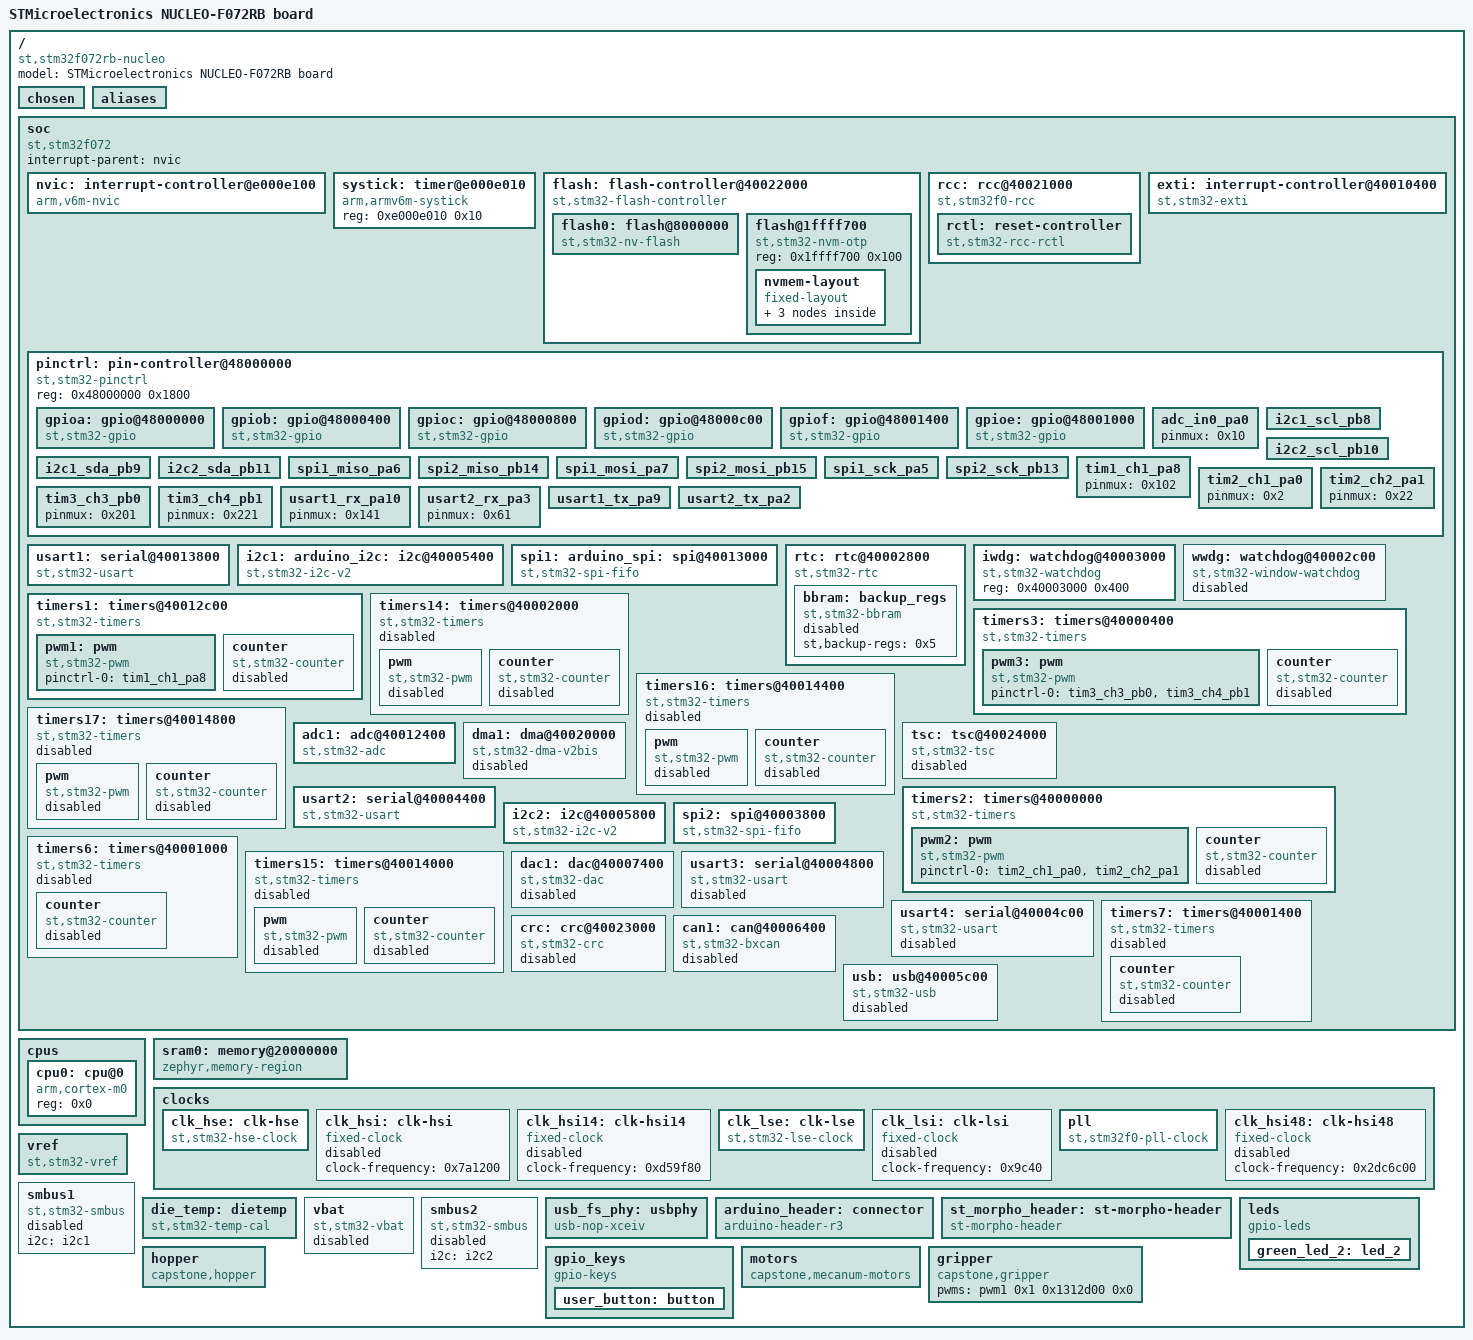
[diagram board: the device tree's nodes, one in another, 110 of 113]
/dts-v1/;

/* node '/' defined in zephyr\dts\common\skeleton.dtsi:9 */
/ {
	#address-cells = < 0x1 >;                         /* in zephyr\dts\common\skeleton.dtsi:10 */
	#size-cells = < 0x1 >;                            /* in zephyr\dts\common\skeleton.dtsi:11 */
	model = "STMicroelectronics NUCLEO-F072RB board"; /* in zephyr\boards\st\nucleo_f072rb\nucleo_f072rb.dts:15 */
	compatible = "st,stm32f072rb-nucleo";             /* in zephyr\boards\st\nucleo_f072rb\nucleo_f072rb.dts:16 */

	/* node '/chosen' defined in zephyr\dts\common\skeleton.dtsi:13 */
	chosen {
		zephyr,flash-controller = &flash; /* in zephyr\dts\arm\st\f0\stm32f0.dtsi:23 */
		zephyr,crc = &crc;                /* in zephyr\dts\arm\st\f0\stm32f071.dtsi:11 */
		zephyr,console = &usart2;         /* in zephyr\boards\st\nucleo_f072rb\nucleo_f072rb.dts:19 */
		zephyr,shell-uart = &usart2;      /* in zephyr\boards\st\nucleo_f072rb\nucleo_f072rb.dts:20 */
		zephyr,sram = &sram0;             /* in zephyr\boards\st\nucleo_f072rb\nucleo_f072rb.dts:21 */
		zephyr,flash = &flash0;           /* in zephyr\boards\st\nucleo_f072rb\nucleo_f072rb.dts:22 */
	};

	/* node '/aliases' defined in zephyr\dts\common\skeleton.dtsi:15 */
	aliases {
		led0 = &green_led_2;   /* in zephyr\boards\st\nucleo_f072rb\nucleo_f072rb.dts:45 */
		sw0 = &user_button;    /* in zephyr\boards\st\nucleo_f072rb\nucleo_f072rb.dts:46 */
		watchdog0 = &iwdg;     /* in zephyr\boards\st\nucleo_f072rb\nucleo_f072rb.dts:47 */
		die-temp0 = &die_temp; /* in zephyr\boards\st\nucleo_f072rb\nucleo_f072rb.dts:48 */
		volt-sensor0 = &vref;  /* in zephyr\boards\st\nucleo_f072rb\nucleo_f072rb.dts:49 */
	};

	/* node '/soc' defined in zephyr\dts\arm\armv6-m.dtsi:6 */
	soc {
		#address-cells = < 0x1 >;     /* in zephyr\dts\arm\armv6-m.dtsi:7 */
		#size-cells = < 0x1 >;        /* in zephyr\dts\arm\armv6-m.dtsi:8 */
		interrupt-parent = < &nvic >; /* in zephyr\dts\arm\armv6-m.dtsi:10 */
		ranges;                       /* in zephyr\dts\arm\armv6-m.dtsi:11 */
		compatible = "st,stm32f072",
		             "st,stm32f0",
		             "simple-bus";    /* in zephyr\dts\arm\st\f0\stm32f072.dtsi:11 */

		/* node '/soc/interrupt-controller@e000e100' defined in zephyr\dts\arm\armv6-m.dtsi:13 */
		nvic: interrupt-controller@e000e100 {
			#address-cells = < 0x1 >;            /* in zephyr\dts\arm\armv6-m.dtsi:14 */
			compatible = "arm,v6m-nvic";         /* in zephyr\dts\arm\armv6-m.dtsi:15 */
			reg = < 0xe000e100 0xc00 >;          /* in zephyr\dts\arm\armv6-m.dtsi:16 */
			interrupt-controller;                /* in zephyr\dts\arm\armv6-m.dtsi:17 */
			#interrupt-cells = < 0x2 >;          /* in zephyr\dts\arm\armv6-m.dtsi:18 */
			arm,num-irq-priority-bits = < 0x2 >; /* in zephyr\dts\arm\st\f0\stm32f0.dtsi:432 */
			phandle = < 0x1 >;                   /* in zephyr\dts\arm\armv6-m.dtsi:10 */
		};

		/* node '/soc/timer@e000e010' defined in zephyr\dts\arm\armv6-m.dtsi:21 */
		systick: timer@e000e010 {
			compatible = "arm,armv6m-systick"; /* in zephyr\dts\arm\armv6-m.dtsi:22 */
			reg = < 0xe000e010 0x10 >;         /* in zephyr\dts\arm\armv6-m.dtsi:23 */
		};

		/* node '/soc/flash-controller@40022000' defined in zephyr\dts\arm\st\f0\stm32f0.dtsi:86 */
		flash: flash-controller@40022000 {
			compatible = "st,stm32-flash-controller",
			             "st,stm32f1-flash-controller"; /* in zephyr\dts\arm\st\f0\stm32f0.dtsi:87 */
			reg = < 0x40022000 0x400 >;                 /* in zephyr\dts\arm\st\f0\stm32f0.dtsi:88 */
			interrupts = < 0x3 0x0 >;                   /* in zephyr\dts\arm\st\f0\stm32f0.dtsi:89 */
			clocks = < &rcc 0x14 0x10 >;                /* in zephyr\dts\arm\st\f0\stm32f0.dtsi:90 */
			#address-cells = < 0x1 >;                   /* in zephyr\dts\arm\st\f0\stm32f0.dtsi:92 */
			#size-cells = < 0x1 >;                      /* in zephyr\dts\arm\st\f0\stm32f0.dtsi:93 */

			/* node '/soc/flash-controller@40022000/flash@8000000' defined in zephyr\dts\arm\st\f0\stm32f0.dtsi:95 */
			flash0: flash@8000000 {
				compatible = "st,stm32-nv-flash",
				             "soc-nv-flash";      /* in zephyr\dts\arm\st\f0\stm32f0.dtsi:96 */
				write-block-size = < 0x2 >;       /* in zephyr\dts\arm\st\f0\stm32f0.dtsi:98 */
				max-erase-time = < 0x28 >;        /* in zephyr\dts\arm\st\f0\stm32f0.dtsi:100 */
				erase-block-size = < 0x800 >;     /* in zephyr\dts\arm\st\f0\stm32f071.dtsi:28 */
				reg = < 0x8000000 0x20000 >;      /* in zephyr\dts\arm\st\f0\stm32f072Xb.dtsi:16 */
			};

			/* node '/soc/flash-controller@40022000/flash@1ffff700' defined in zephyr\dts\arm\st\f0\stm32f0.dtsi:107 */
			flash@1ffff700 {
				compatible = "st,stm32-nvm-otp"; /* in zephyr\dts\arm\st\f0\stm32f0.dtsi:108 */
				reg = < 0x1ffff700 0x100 >;      /* in zephyr\dts\arm\st\f0\stm32f0.dtsi:109 */

				/* node '/soc/flash-controller@40022000/flash@1ffff700/nvmem-layout' defined in zephyr\dts\arm\st\f0\stm32f0.dtsi:111 */
				nvmem-layout {
					compatible = "fixed-layout"; /* in zephyr\dts\arm\st\f0\stm32f0.dtsi:112 */
					#address-cells = < 0x1 >;    /* in zephyr\dts\arm\st\f0\stm32f0.dtsi:113 */
					#size-cells = < 0x1 >;       /* in zephyr\dts\arm\st\f0\stm32f0.dtsi:114 */

					/* node '/soc/flash-controller@40022000/flash@1ffff700/nvmem-layout/ts-cal1@b8' defined in zephyr\dts\arm\st\f0\stm32f0.dtsi:116 */
					ts_cal1_otp: ts-cal1@b8 {
						reg = < 0xb8 0x2 >;          /* in zephyr\dts\arm\st\f0\stm32f0.dtsi:117 */
						#nvmem-cell-cells = < 0x0 >; /* in zephyr\dts\arm\st\f0\stm32f0.dtsi:118 */
						read-only;                   /* in zephyr\dts\arm\st\f0\stm32f0.dtsi:119 */
						phandle = < 0x1f >;          /* in zephyr\dts\arm\st\f0\stm32f031.dtsi:59 */
					};

					/* node '/soc/flash-controller@40022000/flash@1ffff700/nvmem-layout/vrefint@ba' defined in zephyr\dts\arm\st\f0\stm32f0.dtsi:122 */
					vrefint_otp: vrefint@ba {
						reg = < 0xba 0x2 >;          /* in zephyr\dts\arm\st\f0\stm32f0.dtsi:123 */
						#nvmem-cell-cells = < 0x0 >; /* in zephyr\dts\arm\st\f0\stm32f0.dtsi:124 */
						read-only;                   /* in zephyr\dts\arm\st\f0\stm32f0.dtsi:125 */
						phandle = < 0x1c >;          /* in zephyr\dts\arm\st\f0\stm32f0.dtsi:416 */
					};

					/* node '/soc/flash-controller@40022000/flash@1ffff700/nvmem-layout/ts-cal2@c2' defined in zephyr\dts\arm\st\f0\stm32f031.dtsi:47 */
					ts_cal2_otp: ts-cal2@c2 {
						reg = < 0xc2 0x2 >;          /* in zephyr\dts\arm\st\f0\stm32f031.dtsi:48 */
						#nvmem-cell-cells = < 0x0 >; /* in zephyr\dts\arm\st\f0\stm32f031.dtsi:49 */
						read-only;                   /* in zephyr\dts\arm\st\f0\stm32f031.dtsi:50 */
						phandle = < 0x20 >;          /* in zephyr\dts\arm\st\f0\stm32f031.dtsi:59 */
					};
				};
			};
		};

		/* node '/soc/rcc@40021000' defined in zephyr\dts\arm\st\f0\stm32f0.dtsi:131 */
		rcc: rcc@40021000 {
			compatible = "st,stm32f0-rcc";   /* in zephyr\dts\arm\st\f0\stm32f0.dtsi:132 */
			#clock-cells = < 0x2 >;          /* in zephyr\dts\arm\st\f0\stm32f0.dtsi:133 */
			reg = < 0x40021000 0x400 >;      /* in zephyr\dts\arm\st\f0\stm32f0.dtsi:134 */
			clocks = < &pll >;               /* in zephyr\boards\st\nucleo_f072rb\nucleo_f072rb.dts:71 */
			clock-frequency = < 0x2dc6c00 >; /* in zephyr\boards\st\nucleo_f072rb\nucleo_f072rb.dts:72 */
			ahb-prescaler = < 0x1 >;         /* in zephyr\boards\st\nucleo_f072rb\nucleo_f072rb.dts:73 */
			apb1-prescaler = < 0x2 >;        /* in zephyr\boards\st\nucleo_f072rb\nucleo_f072rb.dts:74 */
			phandle = < 0x2 >;               /* in zephyr\dts\arm\st\f0\stm32f0.dtsi:90 */

			/* node '/soc/rcc@40021000/reset-controller' defined in zephyr\dts\arm\st\f0\stm32f0.dtsi:136 */
			rctl: reset-controller {
				compatible = "st,stm32-rcc-rctl"; /* in zephyr\dts\arm\st\f0\stm32f0.dtsi:137 */
				#reset-cells = < 0x1 >;           /* in zephyr\dts\arm\st\f0\stm32f0.dtsi:138 */
				phandle = < 0x4 >;                /* in zephyr\dts\arm\st\f0\stm32f0.dtsi:206 */
			};
		};

		/* node '/soc/interrupt-controller@40010400' defined in zephyr\dts\arm\st\f0\stm32f0.dtsi:142 */
		exti: interrupt-controller@40010400 {
			compatible = "st,stm32-exti"; /* in zephyr\dts\arm\st\f0\stm32f0.dtsi:143 */
			interrupt-controller;         /* in zephyr\dts\arm\st\f0\stm32f0.dtsi:144 */
			#interrupt-cells = < 0x1 >;   /* in zephyr\dts\arm\st\f0\stm32f0.dtsi:145 */
			#address-cells = < 0x0 >;     /* in zephyr\dts\arm\st\f0\stm32f0.dtsi:146 */
			reg = < 0x40010400 0x400 >;   /* in zephyr\dts\arm\st\f0\stm32f0.dtsi:147 */
			clocks = < &rcc 0x18 0x1 >;   /* in zephyr\dts\arm\st\f0\stm32f0.dtsi:148 */
			num-lines = < 0x20 >;         /* in zephyr\dts\arm\st\f0\stm32f0.dtsi:149 */
			interrupts = < 0x5 0x0 >,
			             < 0x6 0x0 >,
			             < 0x7 0x0 >;     /* in zephyr\dts\arm\st\f0\stm32f0.dtsi:150 */
			interrupt-names = "line0-1",
			                  "line2-3",
			                  "line4-15"; /* in zephyr\dts\arm\st\f0\stm32f0.dtsi:151 */
			line-ranges = < 0x0 0x2 >,
			              < 0x2 0x2 >,
			              < 0x4 0xc >;    /* in zephyr\dts\arm\st\f0\stm32f0.dtsi:152 */
		};

		/* node '/soc/pin-controller@48000000' defined in zephyr\dts\arm\st\f0\stm32f0.dtsi:155 */
		pinctrl: pin-controller@48000000 {
			compatible = "st,stm32-pinctrl"; /* in zephyr\dts\arm\st\f0\stm32f0.dtsi:156 */
			#address-cells = < 0x1 >;        /* in zephyr\dts\arm\st\f0\stm32f0.dtsi:157 */
			#size-cells = < 0x1 >;           /* in zephyr\dts\arm\st\f0\stm32f0.dtsi:158 */
			reg = < 0x48000000 0x1800 >;     /* in zephyr\dts\arm\st\f0\stm32f0.dtsi:159 */

			/* node '/soc/pin-controller@48000000/gpio@48000000' defined in zephyr\dts\arm\st\f0\stm32f0.dtsi:161 */
			gpioa: gpio@48000000 {
				compatible = "st,stm32-gpio";   /* in zephyr\dts\arm\st\f0\stm32f0.dtsi:162 */
				gpio-controller;                /* in zephyr\dts\arm\st\f0\stm32f0.dtsi:163 */
				#gpio-cells = < 0x2 >;          /* in zephyr\dts\arm\st\f0\stm32f0.dtsi:164 */
				reg = < 0x48000000 0x400 >;     /* in zephyr\dts\arm\st\f0\stm32f0.dtsi:165 */
				clocks = < &rcc 0x14 0x20000 >; /* in zephyr\dts\arm\st\f0\stm32f0.dtsi:166 */
				phandle = < 0x22 >;             /* in zephyr\boards\st\nucleo_f072rb\arduino_r3_connector.dtsi:15 */
			};

			/* node '/soc/pin-controller@48000000/gpio@48000400' defined in zephyr\dts\arm\st\f0\stm32f0.dtsi:169 */
			gpiob: gpio@48000400 {
				compatible = "st,stm32-gpio";   /* in zephyr\dts\arm\st\f0\stm32f0.dtsi:170 */
				gpio-controller;                /* in zephyr\dts\arm\st\f0\stm32f0.dtsi:171 */
				#gpio-cells = < 0x2 >;          /* in zephyr\dts\arm\st\f0\stm32f0.dtsi:172 */
				reg = < 0x48000400 0x400 >;     /* in zephyr\dts\arm\st\f0\stm32f0.dtsi:173 */
				clocks = < &rcc 0x14 0x40000 >; /* in zephyr\dts\arm\st\f0\stm32f0.dtsi:174 */
				phandle = < 0xc >;              /* in zephyr\boards\st\nucleo_f072rb\nucleo_f072rb.dts:108 */
			};

			/* node '/soc/pin-controller@48000000/gpio@48000800' defined in zephyr\dts\arm\st\f0\stm32f0.dtsi:177 */
			gpioc: gpio@48000800 {
				compatible = "st,stm32-gpio";   /* in zephyr\dts\arm\st\f0\stm32f0.dtsi:178 */
				gpio-controller;                /* in zephyr\dts\arm\st\f0\stm32f0.dtsi:179 */
				#gpio-cells = < 0x2 >;          /* in zephyr\dts\arm\st\f0\stm32f0.dtsi:180 */
				reg = < 0x48000800 0x400 >;     /* in zephyr\dts\arm\st\f0\stm32f0.dtsi:181 */
				clocks = < &rcc 0x14 0x80000 >; /* in zephyr\dts\arm\st\f0\stm32f0.dtsi:182 */
				phandle = < 0x23 >;             /* in zephyr\boards\st\nucleo_f072rb\arduino_r3_connector.dtsi:15 */
			};

			/* node '/soc/pin-controller@48000000/gpio@48000c00' defined in zephyr\dts\arm\st\f0\stm32f0.dtsi:185 */
			gpiod: gpio@48000c00 {
				compatible = "st,stm32-gpio";    /* in zephyr\dts\arm\st\f0\stm32f0.dtsi:186 */
				gpio-controller;                 /* in zephyr\dts\arm\st\f0\stm32f0.dtsi:187 */
				#gpio-cells = < 0x2 >;           /* in zephyr\dts\arm\st\f0\stm32f0.dtsi:188 */
				reg = < 0x48000c00 0x400 >;      /* in zephyr\dts\arm\st\f0\stm32f0.dtsi:189 */
				clocks = < &rcc 0x14 0x100000 >; /* in zephyr\dts\arm\st\f0\stm32f0.dtsi:190 */
				phandle = < 0x24 >;              /* in zephyr\boards\st\nucleo_f072rb\st_morpho_connector.dtsi:15 */
			};

			/* node '/soc/pin-controller@48000000/gpio@48001400' defined in zephyr\dts\arm\st\f0\stm32f0.dtsi:193 */
			gpiof: gpio@48001400 {
				compatible = "st,stm32-gpio";    /* in zephyr\dts\arm\st\f0\stm32f0.dtsi:194 */
				gpio-controller;                 /* in zephyr\dts\arm\st\f0\stm32f0.dtsi:195 */
				#gpio-cells = < 0x2 >;           /* in zephyr\dts\arm\st\f0\stm32f0.dtsi:196 */
				reg = < 0x48001400 0x400 >;      /* in zephyr\dts\arm\st\f0\stm32f0.dtsi:197 */
				clocks = < &rcc 0x14 0x400000 >; /* in zephyr\dts\arm\st\f0\stm32f0.dtsi:198 */
				phandle = < 0x25 >;              /* in zephyr\boards\st\nucleo_f072rb\st_morpho_connector.dtsi:15 */
			};

			/* node '/soc/pin-controller@48000000/gpio@48001000' defined in zephyr\dts\arm\st\f0\stm32f071.dtsi:33 */
			gpioe: gpio@48001000 {
				compatible = "st,stm32-gpio";    /* in zephyr\dts\arm\st\f0\stm32f071.dtsi:34 */
				gpio-controller;                 /* in zephyr\dts\arm\st\f0\stm32f071.dtsi:35 */
				#gpio-cells = < 0x2 >;           /* in zephyr\dts\arm\st\f0\stm32f071.dtsi:36 */
				reg = < 0x48001000 0x400 >;      /* in zephyr\dts\arm\st\f0\stm32f071.dtsi:37 */
				clocks = < &rcc 0x14 0x200000 >; /* in zephyr\dts\arm\st\f0\stm32f071.dtsi:38 */
			};

			/* node '/soc/pin-controller@48000000/adc_in0_pa0' defined in modules\hal\stm32\dts\st\f0\stm32f072r(8-b)tx-pinctrl.dtsi:13 */
			adc_in0_pa0: adc_in0_pa0 {
				pinmux = < 0x10 >;  /* in modules\hal\stm32\dts\st\f0\stm32f072r(8-b)tx-pinctrl.dtsi:14 */
				phandle = < 0x10 >; /* in zephyr\boards\st\nucleo_f072rb\nucleo_f072rb.dts:123 */
			};

			/* node '/soc/pin-controller@48000000/i2c1_scl_pb8' defined in modules\hal\stm32\dts\st\f0\stm32f072r(8-b)tx-pinctrl.dtsi:383 */
			i2c1_scl_pb8: i2c1_scl_pb8 {
				pinmux = < 0x301 >; /* in modules\hal\stm32\dts\st\f0\stm32f072r(8-b)tx-pinctrl.dtsi:384 */
				bias-pull-up;       /* in modules\hal\stm32\dts\st\f0\stm32f072r(8-b)tx-pinctrl.dtsi:385 */
				drive-open-drain;   /* in modules\hal\stm32\dts\st\f0\stm32f072r(8-b)tx-pinctrl.dtsi:386 */
				phandle = < 0x7 >;  /* in zephyr\boards\st\nucleo_f072rb\nucleo_f072rb.dts:92 */
			};

			/* node '/soc/pin-controller@48000000/i2c2_scl_pb10' defined in modules\hal\stm32\dts\st\f0\stm32f072r(8-b)tx-pinctrl.dtsi:389 */
			i2c2_scl_pb10: i2c2_scl_pb10 {
				pinmux = < 0x341 >; /* in modules\hal\stm32\dts\st\f0\stm32f072r(8-b)tx-pinctrl.dtsi:390 */
				bias-pull-up;       /* in modules\hal\stm32\dts\st\f0\stm32f072r(8-b)tx-pinctrl.dtsi:391 */
				drive-open-drain;   /* in modules\hal\stm32\dts\st\f0\stm32f072r(8-b)tx-pinctrl.dtsi:392 */
				phandle = < 0x15 >; /* in zephyr\boards\st\nucleo_f072rb\nucleo_f072rb.dts:99 */
			};

			/* node '/soc/pin-controller@48000000/i2c1_sda_pb9' defined in modules\hal\stm32\dts\st\f0\stm32f072r(8-b)tx-pinctrl.dtsi:409 */
			i2c1_sda_pb9: i2c1_sda_pb9 {
				pinmux = < 0x321 >; /* in modules\hal\stm32\dts\st\f0\stm32f072r(8-b)tx-pinctrl.dtsi:410 */
				bias-pull-up;       /* in modules\hal\stm32\dts\st\f0\stm32f072r(8-b)tx-pinctrl.dtsi:411 */
				drive-open-drain;   /* in modules\hal\stm32\dts\st\f0\stm32f072r(8-b)tx-pinctrl.dtsi:412 */
				phandle = < 0x8 >;  /* in zephyr\boards\st\nucleo_f072rb\nucleo_f072rb.dts:92 */
			};

			/* node '/soc/pin-controller@48000000/i2c2_sda_pb11' defined in modules\hal\stm32\dts\st\f0\stm32f072r(8-b)tx-pinctrl.dtsi:415 */
			i2c2_sda_pb11: i2c2_sda_pb11 {
				pinmux = < 0x361 >; /* in modules\hal\stm32\dts\st\f0\stm32f072r(8-b)tx-pinctrl.dtsi:416 */
				bias-pull-up;       /* in modules\hal\stm32\dts\st\f0\stm32f072r(8-b)tx-pinctrl.dtsi:417 */
				drive-open-drain;   /* in modules\hal\stm32\dts\st\f0\stm32f072r(8-b)tx-pinctrl.dtsi:418 */
				phandle = < 0x16 >; /* in zephyr\boards\st\nucleo_f072rb\nucleo_f072rb.dts:99 */
			};

			/* node '/soc/pin-controller@48000000/spi1_miso_pa6' defined in modules\hal\stm32\dts\st\f0\stm32f072r(8-b)tx-pinctrl.dtsi:533 */
			spi1_miso_pa6: spi1_miso_pa6 {
				pinmux = < 0xc0 >;             /* in modules\hal\stm32\dts\st\f0\stm32f072r(8-b)tx-pinctrl.dtsi:534 */
				bias-pull-down;                /* in modules\hal\stm32\dts\st\f0\stm32f072r(8-b)tx-pinctrl.dtsi:535 */
				slew-rate = "very-high-speed"; /* in modules\hal\stm32\dts\st\f0\stm32f072r(8-b)tx-pinctrl.dtsi:536 */
				phandle = < 0xa >;             /* in zephyr\boards\st\nucleo_f072rb\nucleo_f072rb.dts:106 */
			};

			/* node '/soc/pin-controller@48000000/spi2_miso_pb14' defined in modules\hal\stm32\dts\st\f0\stm32f072r(8-b)tx-pinctrl.dtsi:545 */
			spi2_miso_pb14: spi2_miso_pb14 {
				pinmux = < 0x3c0 >;            /* in modules\hal\stm32\dts\st\f0\stm32f072r(8-b)tx-pinctrl.dtsi:546 */
				bias-pull-down;                /* in modules\hal\stm32\dts\st\f0\stm32f072r(8-b)tx-pinctrl.dtsi:547 */
				slew-rate = "very-high-speed"; /* in modules\hal\stm32\dts\st\f0\stm32f072r(8-b)tx-pinctrl.dtsi:548 */
				phandle = < 0x18 >;            /* in zephyr\boards\st\nucleo_f072rb\nucleo_f072rb.dts:113 */
			};

			/* node '/soc/pin-controller@48000000/spi1_mosi_pa7' defined in modules\hal\stm32\dts\st\f0\stm32f072r(8-b)tx-pinctrl.dtsi:559 */
			spi1_mosi_pa7: spi1_mosi_pa7 {
				pinmux = < 0xe0 >;             /* in modules\hal\stm32\dts\st\f0\stm32f072r(8-b)tx-pinctrl.dtsi:560 */
				bias-pull-down;                /* in modules\hal\stm32\dts\st\f0\stm32f072r(8-b)tx-pinctrl.dtsi:561 */
				slew-rate = "very-high-speed"; /* in modules\hal\stm32\dts\st\f0\stm32f072r(8-b)tx-pinctrl.dtsi:562 */
				phandle = < 0xb >;             /* in zephyr\boards\st\nucleo_f072rb\nucleo_f072rb.dts:106 */
			};

			/* node '/soc/pin-controller@48000000/spi2_mosi_pb15' defined in modules\hal\stm32\dts\st\f0\stm32f072r(8-b)tx-pinctrl.dtsi:571 */
			spi2_mosi_pb15: spi2_mosi_pb15 {
				pinmux = < 0x3e0 >;            /* in modules\hal\stm32\dts\st\f0\stm32f072r(8-b)tx-pinctrl.dtsi:572 */
				bias-pull-down;                /* in modules\hal\stm32\dts\st\f0\stm32f072r(8-b)tx-pinctrl.dtsi:573 */
				slew-rate = "very-high-speed"; /* in modules\hal\stm32\dts\st\f0\stm32f072r(8-b)tx-pinctrl.dtsi:574 */
				phandle = < 0x19 >;            /* in zephyr\boards\st\nucleo_f072rb\nucleo_f072rb.dts:113 */
			};

			/* node '/soc/pin-controller@48000000/spi1_sck_pa5' defined in modules\hal\stm32\dts\st\f0\stm32f072r(8-b)tx-pinctrl.dtsi:611 */
			spi1_sck_pa5: spi1_sck_pa5 {
				pinmux = < 0xa0 >;             /* in modules\hal\stm32\dts\st\f0\stm32f072r(8-b)tx-pinctrl.dtsi:612 */
				bias-pull-down;                /* in modules\hal\stm32\dts\st\f0\stm32f072r(8-b)tx-pinctrl.dtsi:613 */
				slew-rate = "very-high-speed"; /* in modules\hal\stm32\dts\st\f0\stm32f072r(8-b)tx-pinctrl.dtsi:614 */
				phandle = < 0x9 >;             /* in zephyr\boards\st\nucleo_f072rb\nucleo_f072rb.dts:106 */
			};

			/* node '/soc/pin-controller@48000000/spi2_sck_pb13' defined in modules\hal\stm32\dts\st\f0\stm32f072r(8-b)tx-pinctrl.dtsi:629 */
			spi2_sck_pb13: spi2_sck_pb13 {
				pinmux = < 0x3a0 >;            /* in modules\hal\stm32\dts\st\f0\stm32f072r(8-b)tx-pinctrl.dtsi:630 */
				bias-pull-down;                /* in modules\hal\stm32\dts\st\f0\stm32f072r(8-b)tx-pinctrl.dtsi:631 */
				slew-rate = "very-high-speed"; /* in modules\hal\stm32\dts\st\f0\stm32f072r(8-b)tx-pinctrl.dtsi:632 */
				phandle = < 0x17 >;            /* in zephyr\boards\st\nucleo_f072rb\nucleo_f072rb.dts:113 */
			};

			/* node '/soc/pin-controller@48000000/tim1_ch1_pa8' defined in modules\hal\stm32\dts\st\f0\stm32f072r(8-b)tx-pinctrl.dtsi:671 */
			tim1_ch1_pa8: tim1_ch1_pa8 {
				pinmux = < 0x102 >; /* in modules\hal\stm32\dts\st\f0\stm32f072r(8-b)tx-pinctrl.dtsi:672 */
				phandle = < 0xd >;  /* in ..\Documents\capstone\zephyr\nucleo_f072rb.overlay:60 */
			};

			/* node '/soc/pin-controller@48000000/tim2_ch1_pa0' defined in modules\hal\stm32\dts\st\f0\stm32f072r(8-b)tx-pinctrl.dtsi:707 */
			tim2_ch1_pa0: tim2_ch1_pa0 {
				pinmux = < 0x2 >;   /* in modules\hal\stm32\dts\st\f0\stm32f072r(8-b)tx-pinctrl.dtsi:708 */
				phandle = < 0x11 >; /* in ..\Documents\capstone\zephyr\nucleo_f072rb.overlay:33 */
			};

			/* node '/soc/pin-controller@48000000/tim2_ch2_pa1' defined in modules\hal\stm32\dts\st\f0\stm32f072r(8-b)tx-pinctrl.dtsi:711 */
			tim2_ch2_pa1: tim2_ch2_pa1 {
				pinmux = < 0x22 >;  /* in modules\hal\stm32\dts\st\f0\stm32f072r(8-b)tx-pinctrl.dtsi:712 */
				phandle = < 0x12 >; /* in ..\Documents\capstone\zephyr\nucleo_f072rb.overlay:33 */
			};

			/* node '/soc/pin-controller@48000000/tim3_ch3_pb0' defined in modules\hal\stm32\dts\st\f0\stm32f072r(8-b)tx-pinctrl.dtsi:751 */
			tim3_ch3_pb0: tim3_ch3_pb0 {
				pinmux = < 0x201 >; /* in modules\hal\stm32\dts\st\f0\stm32f072r(8-b)tx-pinctrl.dtsi:752 */
				phandle = < 0xe >;  /* in ..\Documents\capstone\zephyr\nucleo_f072rb.overlay:45 */
			};

			/* node '/soc/pin-controller@48000000/tim3_ch4_pb1' defined in modules\hal\stm32\dts\st\f0\stm32f072r(8-b)tx-pinctrl.dtsi:755 */
			tim3_ch4_pb1: tim3_ch4_pb1 {
				pinmux = < 0x221 >; /* in modules\hal\stm32\dts\st\f0\stm32f072r(8-b)tx-pinctrl.dtsi:756 */
				phandle = < 0xf >;  /* in ..\Documents\capstone\zephyr\nucleo_f072rb.overlay:45 */
			};

			/* node '/soc/pin-controller@48000000/usart1_rx_pa10' defined in modules\hal\stm32\dts\st\f0\stm32f072r(8-b)tx-pinctrl.dtsi:1042 */
			usart1_rx_pa10: usart1_rx_pa10 {
				pinmux = < 0x141 >; /* in modules\hal\stm32\dts\st\f0\stm32f072r(8-b)tx-pinctrl.dtsi:1043 */
				phandle = < 0x6 >;  /* in zephyr\boards\st\nucleo_f072rb\nucleo_f072rb.dts:78 */
			};

			/* node '/soc/pin-controller@48000000/usart2_rx_pa3' defined in modules\hal\stm32\dts\st\f0\stm32f072r(8-b)tx-pinctrl.dtsi:1050 */
			usart2_rx_pa3: usart2_rx_pa3 {
				pinmux = < 0x61 >;  /* in modules\hal\stm32\dts\st\f0\stm32f072r(8-b)tx-pinctrl.dtsi:1051 */
				phandle = < 0x14 >; /* in zephyr\boards\st\nucleo_f072rb\nucleo_f072rb.dts:85 */
			};

			/* node '/soc/pin-controller@48000000/usart1_tx_pa9' defined in modules\hal\stm32\dts\st\f0\stm32f072r(8-b)tx-pinctrl.dtsi:1080 */
			usart1_tx_pa9: usart1_tx_pa9 {
				pinmux = < 0x121 >; /* in modules\hal\stm32\dts\st\f0\stm32f072r(8-b)tx-pinctrl.dtsi:1081 */
				bias-pull-up;       /* in modules\hal\stm32\dts\st\f0\stm32f072r(8-b)tx-pinctrl.dtsi:1082 */
				phandle = < 0x5 >;  /* in zephyr\boards\st\nucleo_f072rb\nucleo_f072rb.dts:78 */
			};

			/* node '/soc/pin-controller@48000000/usart2_tx_pa2' defined in modules\hal\stm32\dts\st\f0\stm32f072r(8-b)tx-pinctrl.dtsi:1090 */
			usart2_tx_pa2: usart2_tx_pa2 {
				pinmux = < 0x41 >;  /* in modules\hal\stm32\dts\st\f0\stm32f072r(8-b)tx-pinctrl.dtsi:1091 */
				bias-pull-up;       /* in modules\hal\stm32\dts\st\f0\stm32f072r(8-b)tx-pinctrl.dtsi:1092 */
				phandle = < 0x13 >; /* in zephyr\boards\st\nucleo_f072rb\nucleo_f072rb.dts:85 */
			};
		};

		/* node '/soc/serial@40013800' defined in zephyr\dts\arm\st\f0\stm32f0.dtsi:202 */
		usart1: serial@40013800 {
			compatible = "st,stm32-usart",
			             "st,stm32-uart";                   /* in zephyr\dts\arm\st\f0\stm32f0.dtsi:203 */
			reg = < 0x40013800 0x400 >;                     /* in zephyr\dts\arm\st\f0\stm32f0.dtsi:204 */
			clocks = < &rcc 0x18 0x4000 >;                  /* in zephyr\dts\arm\st\f0\stm32f0.dtsi:205 */
			resets = < &rctl 0x18e >;                       /* in zephyr\dts\arm\st\f0\stm32f0.dtsi:206 */
			interrupts = < 0x1b 0x0 >;                      /* in zephyr\dts\arm\st\f0\stm32f0.dtsi:207 */
			pinctrl-0 = < &usart1_tx_pa9 &usart1_rx_pa10 >; /* in zephyr\boards\st\nucleo_f072rb\nucleo_f072rb.dts:78 */
			pinctrl-names = "default";                      /* in zephyr\boards\st\nucleo_f072rb\nucleo_f072rb.dts:79 */
			current-speed = < 0x1c200 >;                    /* in zephyr\boards\st\nucleo_f072rb\nucleo_f072rb.dts:80 */
			status = "okay";                                /* in zephyr\boards\st\nucleo_f072rb\nucleo_f072rb.dts:81 */
		};

		/* node '/soc/i2c@40005400' defined in zephyr\dts\arm\st\f0\stm32f0.dtsi:211 */
		i2c1: arduino_i2c: i2c@40005400 {
			compatible = "st,stm32-i2c-v2";              /* in zephyr\dts\arm\st\f0\stm32f0.dtsi:212 */
			#address-cells = < 0x1 >;                    /* in zephyr\dts\arm\st\f0\stm32f0.dtsi:214 */
			#size-cells = < 0x0 >;                       /* in zephyr\dts\arm\st\f0\stm32f0.dtsi:215 */
			reg = < 0x40005400 0x400 >;                  /* in zephyr\dts\arm\st\f0\stm32f0.dtsi:216 */
			clocks = < &rcc 0x1c 0x200000 >,
			         < &rcc 0x1 0x1040030 >;             /* in zephyr\dts\arm\st\f0\stm32f0.dtsi:217 */
			interrupts = < 0x17 0x0 >;                   /* in zephyr\dts\arm\st\f0\stm32f0.dtsi:222 */
			interrupt-names = "combined";                /* in zephyr\dts\arm\st\f0\stm32f0.dtsi:223 */
			pinctrl-0 = < &i2c1_scl_pb8 &i2c1_sda_pb9 >; /* in zephyr\boards\st\nucleo_f072rb\nucleo_f072rb.dts:92 */
			pinctrl-names = "default";                   /* in zephyr\boards\st\nucleo_f072rb\nucleo_f072rb.dts:93 */
			status = "okay";                             /* in zephyr\boards\st\nucleo_f072rb\nucleo_f072rb.dts:94 */
			clock-frequency = < 0x61a80 >;               /* in zephyr\boards\st\nucleo_f072rb\nucleo_f072rb.dts:95 */
			phandle = < 0x1e >;                          /* in zephyr\dts\arm\st\f0\stm32f0.dtsi:426 */
		};

		/* node '/soc/spi@40013000' defined in zephyr\dts\arm\st\f0\stm32f0.dtsi:227 */
		spi1: arduino_spi: spi@40013000 {
			compatible = "st,stm32-spi-fifo",
			             "st,stm32-spi";                                 /* in zephyr\dts\arm\st\f0\stm32f0.dtsi:228 */
			#address-cells = < 0x1 >;                                    /* in zephyr\dts\arm\st\f0\stm32f0.dtsi:229 */
			#size-cells = < 0x0 >;                                       /* in zephyr\dts\arm\st\f0\stm32f0.dtsi:230 */
			reg = < 0x40013000 0x400 >;                                  /* in zephyr\dts\arm\st\f0\stm32f0.dtsi:231 */
			clocks = < &rcc 0x18 0x1000 >;                               /* in zephyr\dts\arm\st\f0\stm32f0.dtsi:232 */
			interrupts = < 0x19 0x3 >;                                   /* in zephyr\dts\arm\st\f0\stm32f0.dtsi:233 */
			st,spi-data-width = "full-4-to-16-bit";                      /* in zephyr\dts\arm\st\f0\stm32f0.dtsi:234 */
			pinctrl-0 = < &spi1_sck_pa5 &spi1_miso_pa6 &spi1_mosi_pa7 >; /* in zephyr\boards\st\nucleo_f072rb\nucleo_f072rb.dts:106 */
			pinctrl-names = "default";                                   /* in zephyr\boards\st\nucleo_f072rb\nucleo_f072rb.dts:107 */
			cs-gpios = < &gpiob 0x6 0x11 >;                              /* in zephyr\boards\st\nucleo_f072rb\nucleo_f072rb.dts:108 */
			status = "okay";                                             /* in zephyr\boards\st\nucleo_f072rb\nucleo_f072rb.dts:109 */
		};

		/* node '/soc/rtc@40002800' defined in zephyr\dts\arm\st\f0\stm32f0.dtsi:238 */
		rtc: rtc@40002800 {
			compatible = "st,stm32-rtc";       /* in zephyr\dts\arm\st\f0\stm32f0.dtsi:239 */
			reg = < 0x40002800 0x400 >;        /* in zephyr\dts\arm\st\f0\stm32f0.dtsi:240 */
			interrupts = < 0x2 0x0 >;          /* in zephyr\dts\arm\st\f0\stm32f0.dtsi:242 */
			prescaler = < 0x8000 >;            /* in zephyr\dts\arm\st\f0\stm32f0.dtsi:243 */
			alarms-count = < 0x1 >;            /* in zephyr\dts\arm\st\f0\stm32f0.dtsi:244 */
			alrm-exti-line = < 0x11 >;         /* in zephyr\dts\arm\st\f0\stm32f0.dtsi:245 */
			clocks = < &rcc 0x1c 0x10000000 >,
			         < &rcc 0x2 0x1280020 >;   /* in zephyr\boards\st\nucleo_f072rb\nucleo_f072rb.dts:131 */
			status = "okay";                   /* in zephyr\boards\st\nucleo_f072rb\nucleo_f072rb.dts:133 */

			/* node '/soc/rtc@40002800/backup_regs' defined in zephyr\dts\arm\st\f0\stm32f031.dtsi:37 */
			bbram: backup_regs {
				compatible = "st,stm32-bbram"; /* in zephyr\dts\arm\st\f0\stm32f031.dtsi:38 */
				st,backup-regs = < 0x5 >;      /* in zephyr\dts\arm\st\f0\stm32f031.dtsi:39 */
				status = "disabled";           /* in zephyr\dts\arm\st\f0\stm32f031.dtsi:40 */
			};
		};

		/* node '/soc/watchdog@40003000' defined in zephyr\dts\arm\st\f0\stm32f0.dtsi:249 */
		iwdg: watchdog@40003000 {
			compatible = "st,stm32-watchdog"; /* in zephyr\dts\arm\st\f0\stm32f0.dtsi:250 */
			reg = < 0x40003000 0x400 >;       /* in zephyr\dts\arm\st\f0\stm32f0.dtsi:251 */
			status = "okay";                  /* in zephyr\boards\st\nucleo_f072rb\nucleo_f072rb.dts:119 */
		};

		/* node '/soc/watchdog@40002c00' defined in zephyr\dts\arm\st\f0\stm32f0.dtsi:255 */
		wwdg: watchdog@40002c00 {
			compatible = "st,stm32-window-watchdog"; /* in zephyr\dts\arm\st\f0\stm32f0.dtsi:256 */
			reg = < 0x40002c00 0x400 >;              /* in zephyr\dts\arm\st\f0\stm32f0.dtsi:257 */
			clocks = < &rcc 0x1c 0x800 >;            /* in zephyr\dts\arm\st\f0\stm32f0.dtsi:258 */
			interrupts = < 0x0 0x2 >;                /* in zephyr\dts\arm\st\f0\stm32f0.dtsi:259 */
			status = "disabled";                     /* in zephyr\dts\arm\st\f0\stm32f0.dtsi:260 */
		};

		/* node '/soc/timers@40012c00' defined in zephyr\dts\arm\st\f0\stm32f0.dtsi:263 */
		timers1: timers@40012c00 {
			compatible = "st,stm32-timers";     /* in zephyr\dts\arm\st\f0\stm32f0.dtsi:264 */
			reg = < 0x40012c00 0x400 >;         /* in zephyr\dts\arm\st\f0\stm32f0.dtsi:265 */
			clocks = < &rcc 0x18 0x800 >,
			         < &rcc 0x8 0xff >;         /* in zephyr\dts\arm\st\f0\stm32f0.dtsi:266 */
			resets = < &rctl 0x18b >;           /* in zephyr\dts\arm\st\f0\stm32f0.dtsi:268 */
			interrupts = < 0xd 0x0 >,
			             < 0xe 0x0 >;           /* in zephyr\dts\arm\st\f0\stm32f0.dtsi:269 */
			interrupt-names = "brk_up_trg_com",
			                  "cc";             /* in zephyr\dts\arm\st\f0\stm32f0.dtsi:270 */
			st,prescaler = < 0x2f >;            /* in ..\Documents\capstone\zephyr\nucleo_f072rb.overlay:54 */
			status = "okay";                    /* in ..\Documents\capstone\zephyr\nucleo_f072rb.overlay:55 */

			/* node '/soc/timers@40012c00/pwm' defined in zephyr\dts\arm\st\f0\stm32f0.dtsi:274 */
			pwm1: pwm {
				compatible = "st,stm32-pwm";   /* in zephyr\dts\arm\st\f0\stm32f0.dtsi:275 */
				#pwm-cells = < 0x3 >;          /* in zephyr\dts\arm\st\f0\stm32f0.dtsi:277 */
				status = "okay";               /* in ..\Documents\capstone\zephyr\nucleo_f072rb.overlay:58 */
				pinctrl-0 = < &tim1_ch1_pa8 >; /* in ..\Documents\capstone\zephyr\nucleo_f072rb.overlay:60 */
				pinctrl-names = "default";     /* in ..\Documents\capstone\zephyr\nucleo_f072rb.overlay:61 */
				phandle = < 0x28 >;            /* in ..\Documents\capstone\zephyr\nucleo_f072rb.overlay:83 */
			};

			/* node '/soc/timers@40012c00/counter' defined in zephyr\dts\arm\st\f0\stm32f0.dtsi:280 */
			counter {
				compatible = "st,stm32-counter"; /* in zephyr\dts\arm\st\f0\stm32f0.dtsi:281 */
				status = "disabled";             /* in zephyr\dts\arm\st\f0\stm32f0.dtsi:282 */
			};
		};

		/* node '/soc/timers@40000400' defined in zephyr\dts\arm\st\f0\stm32f0.dtsi:286 */
		timers3: timers@40000400 {
			compatible = "st,stm32-timers"; /* in zephyr\dts\arm\st\f0\stm32f0.dtsi:287 */
			reg = < 0x40000400 0x400 >;     /* in zephyr\dts\arm\st\f0\stm32f0.dtsi:288 */
			clocks = < &rcc 0x1c 0x2 >,
			         < &rcc 0x8 0xff >;     /* in zephyr\dts\arm\st\f0\stm32f0.dtsi:289 */
			resets = < &rctl 0x201 >;       /* in zephyr\dts\arm\st\f0\stm32f0.dtsi:291 */
			interrupts = < 0x10 0x0 >;      /* in zephyr\dts\arm\st\f0\stm32f0.dtsi:292 */
			interrupt-names = "global";     /* in zephyr\dts\arm\st\f0\stm32f0.dtsi:293 */
			st,prescaler = < 0x0 >;         /* in ..\Documents\capstone\zephyr\nucleo_f072rb.overlay:39 */
			status = "okay";                /* in ..\Documents\capstone\zephyr\nucleo_f072rb.overlay:40 */

			/* node '/soc/timers@40000400/pwm' defined in zephyr\dts\arm\st\f0\stm32f0.dtsi:297 */
			pwm3: pwm {
				compatible = "st,stm32-pwm";                 /* in zephyr\dts\arm\st\f0\stm32f0.dtsi:298 */
				#pwm-cells = < 0x3 >;                        /* in zephyr\dts\arm\st\f0\stm32f0.dtsi:300 */
				status = "okay";                             /* in ..\Documents\capstone\zephyr\nucleo_f072rb.overlay:43 */
				pinctrl-0 = < &tim3_ch3_pb0 &tim3_ch4_pb1 >; /* in ..\Documents\capstone\zephyr\nucleo_f072rb.overlay:45 */
				pinctrl-names = "default";                   /* in ..\Documents\capstone\zephyr\nucleo_f072rb.overlay:46 */
				phandle = < 0x27 >;                          /* in ..\Documents\capstone\zephyr\nucleo_f072rb.overlay:69 */
			};

			/* node '/soc/timers@40000400/counter' defined in zephyr\dts\arm\st\f0\stm32f0.dtsi:303 */
			counter {
				compatible = "st,stm32-counter"; /* in zephyr\dts\arm\st\f0\stm32f0.dtsi:304 */
				status = "disabled";             /* in zephyr\dts\arm\st\f0\stm32f0.dtsi:305 */
			};
		};

		/* node '/soc/timers@40002000' defined in zephyr\dts\arm\st\f0\stm32f0.dtsi:309 */
		timers14: timers@40002000 {
			compatible = "st,stm32-timers"; /* in zephyr\dts\arm\st\f0\stm32f0.dtsi:310 */
			reg = < 0x40002000 0x400 >;     /* in zephyr\dts\arm\st\f0\stm32f0.dtsi:311 */
			clocks = < &rcc 0x1c 0x100 >,
			         < &rcc 0x8 0xff >;     /* in zephyr\dts\arm\st\f0\stm32f0.dtsi:312 */
			resets = < &rctl 0x208 >;       /* in zephyr\dts\arm\st\f0\stm32f0.dtsi:314 */
			interrupts = < 0x13 0x0 >;      /* in zephyr\dts\arm\st\f0\stm32f0.dtsi:315 */
			interrupt-names = "global";     /* in zephyr\dts\arm\st\f0\stm32f0.dtsi:316 */
			st,prescaler = < 0x0 >;         /* in zephyr\dts\arm\st\f0\stm32f0.dtsi:317 */
			status = "disabled";            /* in zephyr\dts\arm\st\f0\stm32f0.dtsi:318 */

			/* node '/soc/timers@40002000/pwm' defined in zephyr\dts\arm\st\f0\stm32f0.dtsi:320 */
			pwm {
				compatible = "st,stm32-pwm"; /* in zephyr\dts\arm\st\f0\stm32f0.dtsi:321 */
				status = "disabled";         /* in zephyr\dts\arm\st\f0\stm32f0.dtsi:322 */
				#pwm-cells = < 0x3 >;        /* in zephyr\dts\arm\st\f0\stm32f0.dtsi:323 */
			};

			/* node '/soc/timers@40002000/counter' defined in zephyr\dts\arm\st\f0\stm32f0.dtsi:326 */
			counter {
				compatible = "st,stm32-counter"; /* in zephyr\dts\arm\st\f0\stm32f0.dtsi:327 */
				status = "disabled";             /* in zephyr\dts\arm\st\f0\stm32f0.dtsi:328 */
			};
		};

		/* node '/soc/timers@40014400' defined in zephyr\dts\arm\st\f0\stm32f0.dtsi:332 */
		timers16: timers@40014400 {
			compatible = "st,stm32-timers"; /* in zephyr\dts\arm\st\f0\stm32f0.dtsi:333 */
			reg = < 0x40014400 0x400 >;     /* in zephyr\dts\arm\st\f0\stm32f0.dtsi:334 */
			clocks = < &rcc 0x18 0x20000 >,
			         < &rcc 0x8 0xff >;     /* in zephyr\dts\arm\st\f0\stm32f0.dtsi:335 */
			resets = < &rctl 0x191 >;       /* in zephyr\dts\arm\st\f0\stm32f0.dtsi:337 */
			interrupts = < 0x15 0x0 >;      /* in zephyr\dts\arm\st\f0\stm32f0.dtsi:338 */
			interrupt-names = "global";     /* in zephyr\dts\arm\st\f0\stm32f0.dtsi:339 */
			st,prescaler = < 0x0 >;         /* in zephyr\dts\arm\st\f0\stm32f0.dtsi:340 */
			status = "disabled";            /* in zephyr\dts\arm\st\f0\stm32f0.dtsi:341 */

			/* node '/soc/timers@40014400/pwm' defined in zephyr\dts\arm\st\f0\stm32f0.dtsi:343 */
			pwm {
				compatible = "st,stm32-pwm"; /* in zephyr\dts\arm\st\f0\stm32f0.dtsi:344 */
				status = "disabled";         /* in zephyr\dts\arm\st\f0\stm32f0.dtsi:345 */
				#pwm-cells = < 0x3 >;        /* in zephyr\dts\arm\st\f0\stm32f0.dtsi:346 */
			};

			/* node '/soc/timers@40014400/counter' defined in zephyr\dts\arm\st\f0\stm32f0.dtsi:349 */
			counter {
				compatible = "st,stm32-counter"; /* in zephyr\dts\arm\st\f0\stm32f0.dtsi:350 */
				status = "disabled";             /* in zephyr\dts\arm\st\f0\stm32f0.dtsi:351 */
			};
		};

		/* node '/soc/timers@40014800' defined in zephyr\dts\arm\st\f0\stm32f0.dtsi:355 */
		timers17: timers@40014800 {
			compatible = "st,stm32-timers"; /* in zephyr\dts\arm\st\f0\stm32f0.dtsi:356 */
			reg = < 0x40014800 0x400 >;     /* in zephyr\dts\arm\st\f0\stm32f0.dtsi:357 */
			clocks = < &rcc 0x18 0x40000 >,
			         < &rcc 0x8 0xff >;     /* in zephyr\dts\arm\st\f0\stm32f0.dtsi:358 */
			resets = < &rctl 0x192 >;       /* in zephyr\dts\arm\st\f0\stm32f0.dtsi:360 */
			interrupts = < 0x16 0x0 >;      /* in zephyr\dts\arm\st\f0\stm32f0.dtsi:361 */
			interrupt-names = "global";     /* in zephyr\dts\arm\st\f0\stm32f0.dtsi:362 */
			st,prescaler = < 0x0 >;         /* in zephyr\dts\arm\st\f0\stm32f0.dtsi:363 */
			status = "disabled";            /* in zephyr\dts\arm\st\f0\stm32f0.dtsi:364 */

			/* node '/soc/timers@40014800/pwm' defined in zephyr\dts\arm\st\f0\stm32f0.dtsi:366 */
			pwm {
				compatible = "st,stm32-pwm"; /* in zephyr\dts\arm\st\f0\stm32f0.dtsi:367 */
				status = "disabled";         /* in zephyr\dts\arm\st\f0\stm32f0.dtsi:368 */
				#pwm-cells = < 0x3 >;        /* in zephyr\dts\arm\st\f0\stm32f0.dtsi:369 */
			};

			/* node '/soc/timers@40014800/counter' defined in zephyr\dts\arm\st\f0\stm32f0.dtsi:372 */
			counter {
				compatible = "st,stm32-counter"; /* in zephyr\dts\arm\st\f0\stm32f0.dtsi:373 */
				status = "disabled";             /* in zephyr\dts\arm\st\f0\stm32f0.dtsi:374 */
			};
		};

		/* node '/soc/adc@40012400' defined in zephyr\dts\arm\st\f0\stm32f0.dtsi:378 */
		adc1: adc@40012400 {
			compatible = "st,stm32-adc";                               /* in zephyr\dts\arm\st\f0\stm32f0.dtsi:379 */
			reg = < 0x40012400 0x400 >;                                /* in zephyr\dts\arm\st\f0\stm32f0.dtsi:380 */
			clocks = < &rcc 0x18 0x200 >;                              /* in zephyr\dts\arm\st\f0\stm32f0.dtsi:381 */
			clock-names = "adcx";                                      /* in zephyr\dts\arm\st\f0\stm32f0.dtsi:382 */
			interrupts = < 0xc 0x0 >;                                  /* in zephyr\dts\arm\st\f0\stm32f0.dtsi:383 */
			#io-channel-cells = < 0x1 >;                               /* in zephyr\dts\arm\st\f0\stm32f0.dtsi:384 */
			st,adc-resolutions = < 0xc 0xa 0x8 0x6 >;                  /* in zephyr\dts\arm\st\f0\stm32f0.dtsi:385 */
			sampling-times = < 0x2 0x8 0xe 0x1d 0x2a 0x38 0x48 0xf0 >; /* in zephyr\dts\arm\st\f0\stm32f0.dtsi:386 */
			num-sampling-time-common-channels = < 0x1 >;               /* in zephyr\dts\arm\st\f0\stm32f0.dtsi:387 */
			st,adc-sequencer = "fixed";                                /* in zephyr\dts\arm\st\f0\stm32f0.dtsi:388 */
			st,adc-oversampler = "none";                               /* in zephyr\dts\arm\st\f0\stm32f0.dtsi:389 */
			st,adc-internal-regulator = "none";                        /* in zephyr\dts\arm\st\f0\stm32f0.dtsi:390 */
			pinctrl-0 = < &adc_in0_pa0 >;                              /* in zephyr\boards\st\nucleo_f072rb\nucleo_f072rb.dts:123 */
			pinctrl-names = "default";                                 /* in zephyr\boards\st\nucleo_f072rb\nucleo_f072rb.dts:124 */
			st,adc-clock-source = "SYNC";                              /* in zephyr\boards\st\nucleo_f072rb\nucleo_f072rb.dts:125 */
			st,adc-prescaler = < 0x4 >;                                /* in zephyr\boards\st\nucleo_f072rb\nucleo_f072rb.dts:126 */
			status = "okay";                                           /* in zephyr\boards\st\nucleo_f072rb\nucleo_f072rb.dts:127 */
			phandle = < 0x1d >;                                        /* in zephyr\dts\arm\st\f0\stm32f0.dtsi:418 */
		};

		/* node '/soc/dma@40020000' defined in zephyr\dts\arm\st\f0\stm32f0.dtsi:394 */
		dma1: dma@40020000 {
			compatible = "st,stm32-dma-v2bis";                                        /* in zephyr\dts\arm\st\f0\stm32f0.dtsi:395 */
			#dma-cells = < 0x2 >;                                                     /* in zephyr\dts\arm\st\f0\stm32f0.dtsi:396 */
			reg = < 0x40020000 0x400 >;                                               /* in zephyr\dts\arm\st\f0\stm32f0.dtsi:397 */
			clocks = < &rcc 0x14 0x1 >;                                               /* in zephyr\dts\arm\st\f0\stm32f0.dtsi:398 */
			status = "disabled";                                                      /* in zephyr\dts\arm\st\f0\stm32f0.dtsi:400 */
			interrupts = < 0x9 0x0 0xa 0x0 0xa 0x0 0xb 0x0 0xb 0x0 0xb 0x0 0xb 0x0 >; /* in zephyr\dts\arm\st\f0\stm32f071.dtsi:83 */
		};

		/* node '/soc/tsc@40024000' defined in zephyr\dts\arm\st\f0\stm32f0.dtsi:403 */
		tsc: tsc@40024000 {
			compatible = "st,stm32-tsc";      /* in zephyr\dts\arm\st\f0\stm32f0.dtsi:404 */
			reg = < 0x40024000 0x400 >;       /* in zephyr\dts\arm\st\f0\stm32f0.dtsi:405 */
			clocks = < &rcc 0x14 0x1000000 >; /* in zephyr\dts\arm\st\f0\stm32f0.dtsi:406 */
			resets = < &rctl 0x518 >;         /* in zephyr\dts\arm\st\f0\stm32f0.dtsi:407 */
			interrupts = < 0x8 0x0 >;         /* in zephyr\dts\arm\st\f0\stm32f0.dtsi:408 */
			interrupt-names = "global";       /* in zephyr\dts\arm\st\f0\stm32f0.dtsi:409 */
			status = "disabled";              /* in zephyr\dts\arm\st\f0\stm32f0.dtsi:410 */
		};

		/* node '/soc/timers@40000000' defined in zephyr\dts\arm\st\f0\stm32f031.dtsi:13 */
		timers2: timers@40000000 {
			compatible = "st,stm32-timers"; /* in zephyr\dts\arm\st\f0\stm32f031.dtsi:14 */
			reg = < 0x40000000 0x400 >;     /* in zephyr\dts\arm\st\f0\stm32f031.dtsi:15 */
			clocks = < &rcc 0x1c 0x1 >,
			         < &rcc 0x8 0xff >;     /* in zephyr\dts\arm\st\f0\stm32f031.dtsi:16 */
			resets = < &rctl 0x200 >;       /* in zephyr\dts\arm\st\f0\stm32f031.dtsi:18 */
			interrupts = < 0xf 0x0 >;       /* in zephyr\dts\arm\st\f0\stm32f031.dtsi:19 */
			interrupt-names = "global";     /* in zephyr\dts\arm\st\f0\stm32f031.dtsi:20 */
			st,prescaler = < 0x0 >;         /* in ..\Documents\capstone\zephyr\nucleo_f072rb.overlay:27 */
			status = "okay";                /* in ..\Documents\capstone\zephyr\nucleo_f072rb.overlay:28 */

			/* node '/soc/timers@40000000/pwm' defined in zephyr\dts\arm\st\f0\stm32f031.dtsi:24 */
			pwm2: pwm {
				compatible = "st,stm32-pwm";                 /* in zephyr\dts\arm\st\f0\stm32f031.dtsi:25 */
				#pwm-cells = < 0x3 >;                        /* in zephyr\dts\arm\st\f0\stm32f031.dtsi:27 */
				status = "okay";                             /* in ..\Documents\capstone\zephyr\nucleo_f072rb.overlay:31 */
				pinctrl-0 = < &tim2_ch1_pa0 &tim2_ch2_pa1 >; /* in ..\Documents\capstone\zephyr\nucleo_f072rb.overlay:33 */
				pinctrl-names = "default";                   /* in ..\Documents\capstone\zephyr\nucleo_f072rb.overlay:34 */
				phandle = < 0x26 >;                          /* in ..\Documents\capstone\zephyr\nucleo_f072rb.overlay:69 */
			};

			/* node '/soc/timers@40000000/counter' defined in zephyr\dts\arm\st\f0\stm32f031.dtsi:30 */
			counter {
				compatible = "st,stm32-counter"; /* in zephyr\dts\arm\st\f0\stm32f031.dtsi:31 */
				status = "disabled";             /* in zephyr\dts\arm\st\f0\stm32f031.dtsi:32 */
			};
		};

		/* node '/soc/serial@40004400' defined in zephyr\dts\arm\st\f0\stm32f051.dtsi:13 */
		usart2: serial@40004400 {
			compatible = "st,stm32-usart",
			             "st,stm32-uart";                  /* in zephyr\dts\arm\st\f0\stm32f051.dtsi:14 */
			reg = < 0x40004400 0x400 >;                    /* in zephyr\dts\arm\st\f0\stm32f051.dtsi:15 */
			clocks = < &rcc 0x1c 0x20000 >;                /* in zephyr\dts\arm\st\f0\stm32f051.dtsi:16 */
			resets = < &rctl 0x211 >;                      /* in zephyr\dts\arm\st\f0\stm32f051.dtsi:17 */
			interrupts = < 0x1c 0x0 >;                     /* in zephyr\dts\arm\st\f0\stm32f051.dtsi:18 */
			pinctrl-0 = < &usart2_tx_pa2 &usart2_rx_pa3 >; /* in zephyr\boards\st\nucleo_f072rb\nucleo_f072rb.dts:85 */
			pinctrl-names = "default";                     /* in zephyr\boards\st\nucleo_f072rb\nucleo_f072rb.dts:86 */
			current-speed = < 0x1c200 >;                   /* in zephyr\boards\st\nucleo_f072rb\nucleo_f072rb.dts:87 */
			status = "okay";                               /* in zephyr\boards\st\nucleo_f072rb\nucleo_f072rb.dts:88 */
		};

		/* node '/soc/i2c@40005800' defined in zephyr\dts\arm\st\f0\stm32f051.dtsi:22 */
		i2c2: i2c@40005800 {
			compatible = "st,stm32-i2c-v2";                /* in zephyr\dts\arm\st\f0\stm32f051.dtsi:23 */
			#address-cells = < 0x1 >;                      /* in zephyr\dts\arm\st\f0\stm32f051.dtsi:25 */
			#size-cells = < 0x0 >;                         /* in zephyr\dts\arm\st\f0\stm32f051.dtsi:26 */
			reg = < 0x40005800 0x400 >;                    /* in zephyr\dts\arm\st\f0\stm32f051.dtsi:27 */
			clocks = < &rcc 0x1c 0x400000 >;               /* in zephyr\dts\arm\st\f0\stm32f051.dtsi:28 */
			interrupts = < 0x18 0x0 >;                     /* in zephyr\dts\arm\st\f0\stm32f051.dtsi:29 */
			interrupt-names = "combined";                  /* in zephyr\dts\arm\st\f0\stm32f051.dtsi:30 */
			pinctrl-0 = < &i2c2_scl_pb10 &i2c2_sda_pb11 >; /* in zephyr\boards\st\nucleo_f072rb\nucleo_f072rb.dts:99 */
			pinctrl-names = "default";                     /* in zephyr\boards\st\nucleo_f072rb\nucleo_f072rb.dts:100 */
			status = "okay";                               /* in zephyr\boards\st\nucleo_f072rb\nucleo_f072rb.dts:101 */
			clock-frequency = < 0x61a80 >;                 /* in zephyr\boards\st\nucleo_f072rb\nucleo_f072rb.dts:102 */
			phandle = < 0x21 >;                            /* in zephyr\dts\arm\st\f0\stm32f051.dtsi:98 */
		};

		/* node '/soc/spi@40003800' defined in zephyr\dts\arm\st\f0\stm32f051.dtsi:34 */
		spi2: spi@40003800 {
			compatible = "st,stm32-spi-fifo",
			             "st,stm32-spi";                                    /* in zephyr\dts\arm\st\f0\stm32f051.dtsi:35 */
			#address-cells = < 0x1 >;                                       /* in zephyr\dts\arm\st\f0\stm32f051.dtsi:36 */
			#size-cells = < 0x0 >;                                          /* in zephyr\dts\arm\st\f0\stm32f051.dtsi:37 */
			reg = < 0x40003800 0x400 >;                                     /* in zephyr\dts\arm\st\f0\stm32f051.dtsi:38 */
			clocks = < &rcc 0x1c 0x4000 >;                                  /* in zephyr\dts\arm\st\f0\stm32f051.dtsi:39 */
			interrupts = < 0x1a 0x3 >;                                      /* in zephyr\dts\arm\st\f0\stm32f051.dtsi:40 */
			st,spi-data-width = "full-4-to-16-bit";                         /* in zephyr\dts\arm\st\f0\stm32f051.dtsi:41 */
			pinctrl-0 = < &spi2_sck_pb13 &spi2_miso_pb14 &spi2_mosi_pb15 >; /* in zephyr\boards\st\nucleo_f072rb\nucleo_f072rb.dts:113 */
			pinctrl-names = "default";                                      /* in zephyr\boards\st\nucleo_f072rb\nucleo_f072rb.dts:114 */
			status = "okay";                                                /* in zephyr\boards\st\nucleo_f072rb\nucleo_f072rb.dts:115 */
		};

		/* node '/soc/timers@40001000' defined in zephyr\dts\arm\st\f0\stm32f051.dtsi:45 */
		timers6: timers@40001000 {
			compatible = "st,stm32-timers"; /* in zephyr\dts\arm\st\f0\stm32f051.dtsi:46 */
			reg = < 0x40001000 0x400 >;     /* in zephyr\dts\arm\st\f0\stm32f051.dtsi:47 */
			clocks = < &rcc 0x1c 0x10 >,
			         < &rcc 0x8 0xff >;     /* in zephyr\dts\arm\st\f0\stm32f051.dtsi:48 */
			resets = < &rctl 0x204 >;       /* in zephyr\dts\arm\st\f0\stm32f051.dtsi:50 */
			interrupts = < 0x11 0x0 >;      /* in zephyr\dts\arm\st\f0\stm32f051.dtsi:51 */
			interrupt-names = "global";     /* in zephyr\dts\arm\st\f0\stm32f051.dtsi:52 */
			st,prescaler = < 0x0 >;         /* in zephyr\dts\arm\st\f0\stm32f051.dtsi:53 */
			status = "disabled";            /* in zephyr\dts\arm\st\f0\stm32f051.dtsi:54 */

			/* node '/soc/timers@40001000/counter' defined in zephyr\dts\arm\st\f0\stm32f051.dtsi:56 */
			counter {
				compatible = "st,stm32-counter"; /* in zephyr\dts\arm\st\f0\stm32f051.dtsi:57 */
				status = "disabled";             /* in zephyr\dts\arm\st\f0\stm32f051.dtsi:58 */
			};
		};

		/* node '/soc/timers@40014000' defined in zephyr\dts\arm\st\f0\stm32f051.dtsi:62 */
		timers15: timers@40014000 {
			compatible = "st,stm32-timers"; /* in zephyr\dts\arm\st\f0\stm32f051.dtsi:63 */
			reg = < 0x40014000 0x400 >;     /* in zephyr\dts\arm\st\f0\stm32f051.dtsi:64 */
			clocks = < &rcc 0x18 0x10000 >,
			         < &rcc 0x8 0xff >;     /* in zephyr\dts\arm\st\f0\stm32f051.dtsi:65 */
			resets = < &rctl 0x190 >;       /* in zephyr\dts\arm\st\f0\stm32f051.dtsi:67 */
			interrupts = < 0x14 0x0 >;      /* in zephyr\dts\arm\st\f0\stm32f051.dtsi:68 */
			interrupt-names = "global";     /* in zephyr\dts\arm\st\f0\stm32f051.dtsi:69 */
			st,prescaler = < 0x0 >;         /* in zephyr\dts\arm\st\f0\stm32f051.dtsi:70 */
			status = "disabled";            /* in zephyr\dts\arm\st\f0\stm32f051.dtsi:71 */

			/* node '/soc/timers@40014000/pwm' defined in zephyr\dts\arm\st\f0\stm32f051.dtsi:73 */
			pwm {
				compatible = "st,stm32-pwm"; /* in zephyr\dts\arm\st\f0\stm32f051.dtsi:74 */
				status = "disabled";         /* in zephyr\dts\arm\st\f0\stm32f051.dtsi:75 */
				#pwm-cells = < 0x3 >;        /* in zephyr\dts\arm\st\f0\stm32f051.dtsi:76 */
			};

			/* node '/soc/timers@40014000/counter' defined in zephyr\dts\arm\st\f0\stm32f051.dtsi:79 */
			counter {
				compatible = "st,stm32-counter"; /* in zephyr\dts\arm\st\f0\stm32f051.dtsi:80 */
				status = "disabled";             /* in zephyr\dts\arm\st\f0\stm32f051.dtsi:81 */
			};
		};

		/* node '/soc/dac@40007400' defined in zephyr\dts\arm\st\f0\stm32f051.dtsi:85 */
		dac1: dac@40007400 {
			compatible = "st,stm32-dac";       /* in zephyr\dts\arm\st\f0\stm32f051.dtsi:86 */
			reg = < 0x40007400 0x400 >;        /* in zephyr\dts\arm\st\f0\stm32f051.dtsi:87 */
			clocks = < &rcc 0x1c 0x20000000 >; /* in zephyr\dts\arm\st\f0\stm32f051.dtsi:88 */
			status = "disabled";               /* in zephyr\dts\arm\st\f0\stm32f051.dtsi:89 */
			#io-channel-cells = < 0x1 >;       /* in zephyr\dts\arm\st\f0\stm32f051.dtsi:90 */
		};

		/* node '/soc/serial@40004800' defined in zephyr\dts\arm\st\f0\stm32f071.dtsi:47 */
		usart3: serial@40004800 {
			compatible = "st,stm32-usart",
			             "st,stm32-uart";   /* in zephyr\dts\arm\st\f0\stm32f071.dtsi:48 */
			reg = < 0x40004800 0x400 >;     /* in zephyr\dts\arm\st\f0\stm32f071.dtsi:49 */
			clocks = < &rcc 0x1c 0x40000 >; /* in zephyr\dts\arm\st\f0\stm32f071.dtsi:50 */
			resets = < &rctl 0x212 >;       /* in zephyr\dts\arm\st\f0\stm32f071.dtsi:51 */
			interrupts = < 0x1d 0x0 >;      /* in zephyr\dts\arm\st\f0\stm32f071.dtsi:52 */
			status = "disabled";            /* in zephyr\dts\arm\st\f0\stm32f071.dtsi:53 */
		};

		/* node '/soc/serial@40004c00' defined in zephyr\dts\arm\st\f0\stm32f071.dtsi:56 */
		usart4: serial@40004c00 {
			compatible = "st,stm32-usart",
			             "st,stm32-uart";   /* in zephyr\dts\arm\st\f0\stm32f071.dtsi:57 */
			reg = < 0x40004c00 0x400 >;     /* in zephyr\dts\arm\st\f0\stm32f071.dtsi:58 */
			clocks = < &rcc 0x1c 0x80000 >; /* in zephyr\dts\arm\st\f0\stm32f071.dtsi:59 */
			resets = < &rctl 0x213 >;       /* in zephyr\dts\arm\st\f0\stm32f071.dtsi:60 */
			interrupts = < 0x1d 0x0 >;      /* in zephyr\dts\arm\st\f0\stm32f071.dtsi:61 */
			status = "disabled";            /* in zephyr\dts\arm\st\f0\stm32f071.dtsi:62 */
		};

		/* node '/soc/timers@40001400' defined in zephyr\dts\arm\st\f0\stm32f071.dtsi:65 */
		timers7: timers@40001400 {
			compatible = "st,stm32-timers"; /* in zephyr\dts\arm\st\f0\stm32f071.dtsi:66 */
			reg = < 0x40001400 0x400 >;     /* in zephyr\dts\arm\st\f0\stm32f071.dtsi:67 */
			clocks = < &rcc 0x1c 0x20 >,
			         < &rcc 0x8 0xff >;     /* in zephyr\dts\arm\st\f0\stm32f071.dtsi:68 */
			resets = < &rctl 0x205 >;       /* in zephyr\dts\arm\st\f0\stm32f071.dtsi:70 */
			interrupts = < 0x12 0x0 >;      /* in zephyr\dts\arm\st\f0\stm32f071.dtsi:71 */
			interrupt-names = "global";     /* in zephyr\dts\arm\st\f0\stm32f071.dtsi:72 */
			st,prescaler = < 0x0 >;         /* in zephyr\dts\arm\st\f0\stm32f071.dtsi:73 */
			status = "disabled";            /* in zephyr\dts\arm\st\f0\stm32f071.dtsi:74 */

			/* node '/soc/timers@40001400/counter' defined in zephyr\dts\arm\st\f0\stm32f071.dtsi:76 */
			counter {
				compatible = "st,stm32-counter"; /* in zephyr\dts\arm\st\f0\stm32f071.dtsi:77 */
				status = "disabled";             /* in zephyr\dts\arm\st\f0\stm32f071.dtsi:78 */
			};
		};

		/* node '/soc/crc@40023000' defined in zephyr\dts\arm\st\f0\stm32f071.dtsi:91 */
		crc: crc@40023000 {
			compatible = "st,stm32-crc"; /* in zephyr\dts\arm\st\f0\stm32f071.dtsi:92 */
			reg = < 0x40023000 0x400 >;  /* in zephyr\dts\arm\st\f0\stm32f071.dtsi:93 */
			clocks = < &rcc 0x14 0x40 >; /* in zephyr\dts\arm\st\f0\stm32f071.dtsi:94 */
			status = "disabled";         /* in zephyr\dts\arm\st\f0\stm32f071.dtsi:95 */
		};

		/* node '/soc/can@40006400' defined in zephyr\dts\arm\st\f0\stm32f072.dtsi:13 */
		can1: can@40006400 {
			compatible = "st,stm32-bxcan";    /* in zephyr\dts\arm\st\f0\stm32f072.dtsi:14 */
			reg = < 0x40006400 0x400 >;       /* in zephyr\dts\arm\st\f0\stm32f072.dtsi:15 */
			interrupts = < 0x1e 0x0 >;        /* in zephyr\dts\arm\st\f0\stm32f072.dtsi:16 */
			clocks = < &rcc 0x1c 0x2000000 >; /* in zephyr\dts\arm\st\f0\stm32f072.dtsi:17 */
			status = "disabled";              /* in zephyr\dts\arm\st\f0\stm32f072.dtsi:18 */
		};

		/* node '/soc/usb@40005c00' defined in zephyr\dts\arm\st\f0\stm32f072.dtsi:21 */
		usb: usb@40005c00 {
			compatible = "st,stm32-usb";     /* in zephyr\dts\arm\st\f0\stm32f072.dtsi:22 */
			reg = < 0x40005c00 0x400 >;      /* in zephyr\dts\arm\st\f0\stm32f072.dtsi:23 */
			interrupts = < 0x1f 0x0 >;       /* in zephyr\dts\arm\st\f0\stm32f072.dtsi:24 */
			interrupt-names = "usb";         /* in zephyr\dts\arm\st\f0\stm32f072.dtsi:25 */
			num-bidir-endpoints = < 0x8 >;   /* in zephyr\dts\arm\st\f0\stm32f072.dtsi:26 */
			ram-size = < 0x400 >;            /* in zephyr\dts\arm\st\f0\stm32f072.dtsi:27 */
			maximum-speed = "full-speed";    /* in zephyr\dts\arm\st\f0\stm32f072.dtsi:28 */
			phys = < &usb_fs_phy >;          /* in zephyr\dts\arm\st\f0\stm32f072.dtsi:29 */
			clocks = < &rcc 0x1c 0x800000 >,
			         < &rcc 0x9 0x1070030 >; /* in zephyr\dts\arm\st\f0\stm32f072.dtsi:30 */
			status = "disabled";             /* in zephyr\dts\arm\st\f0\stm32f072.dtsi:32 */
		};
	};

	/* node '/cpus' defined in zephyr\dts\arm\st\f0\stm32f0.dtsi:26 */
	cpus {
		#address-cells = < 0x1 >; /* in zephyr\dts\arm\st\f0\stm32f0.dtsi:27 */
		#size-cells = < 0x0 >;    /* in zephyr\dts\arm\st\f0\stm32f0.dtsi:28 */

		/* node '/cpus/cpu@0' defined in zephyr\dts\arm\st\f0\stm32f0.dtsi:30 */
		cpu0: cpu@0 {
			device_type = "cpu";          /* in zephyr\dts\arm\st\f0\stm32f0.dtsi:31 */
			compatible = "arm,cortex-m0"; /* in zephyr\dts\arm\st\f0\stm32f0.dtsi:32 */
			reg = < 0x0 >;                /* in zephyr\dts\arm\st\f0\stm32f0.dtsi:33 */
		};
	};

	/* node '/memory@20000000' defined in zephyr\dts\arm\st\f0\stm32f0.dtsi:37 */
	sram0: memory@20000000 {
		compatible = "zephyr,memory-region",
		             "mmio-sram";            /* in zephyr\dts\arm\st\f0\stm32f0.dtsi:38 */
		zephyr,memory-region = "SRAM0";      /* in zephyr\dts\arm\st\f0\stm32f0.dtsi:39 */
		reg = < 0x20000000 0x4000 >;         /* in zephyr\dts\arm\st\f0\stm32f072Xb.dtsi:10 */
	};

	/* node '/clocks' defined in zephyr\dts\arm\st\f0\stm32f0.dtsi:42 */
	clocks {

		/* node '/clocks/clk-hse' defined in zephyr\dts\arm\st\f0\stm32f0.dtsi:43 */
		clk_hse: clk-hse {
			#clock-cells = < 0x0 >;            /* in zephyr\dts\arm\st\f0\stm32f0.dtsi:44 */
			compatible = "st,stm32-hse-clock"; /* in zephyr\dts\arm\st\f0\stm32f0.dtsi:45 */
			hse-bypass;                        /* in zephyr\boards\st\nucleo_f072rb\nucleo_f072rb.dts:58 */
			clock-frequency = < 0x7a1200 >;    /* in zephyr\boards\st\nucleo_f072rb\nucleo_f072rb.dts:59 */
			status = "okay";                   /* in zephyr\boards\st\nucleo_f072rb\nucleo_f072rb.dts:60 */
			phandle = < 0x1b >;                /* in zephyr\boards\st\nucleo_f072rb\nucleo_f072rb.dts:64 */
		};

		/* node '/clocks/clk-hsi' defined in zephyr\dts\arm\st\f0\stm32f0.dtsi:49 */
		clk_hsi: clk-hsi {
			#clock-cells = < 0x0 >;         /* in zephyr\dts\arm\st\f0\stm32f0.dtsi:50 */
			compatible = "fixed-clock";     /* in zephyr\dts\arm\st\f0\stm32f0.dtsi:51 */
			clock-frequency = < 0x7a1200 >; /* in zephyr\dts\arm\st\f0\stm32f0.dtsi:52 */
			status = "disabled";            /* in zephyr\dts\arm\st\f0\stm32f0.dtsi:53 */
		};

		/* node '/clocks/clk-hsi14' defined in zephyr\dts\arm\st\f0\stm32f0.dtsi:56 */
		clk_hsi14: clk-hsi14 {
			#clock-cells = < 0x0 >;         /* in zephyr\dts\arm\st\f0\stm32f0.dtsi:57 */
			compatible = "fixed-clock";     /* in zephyr\dts\arm\st\f0\stm32f0.dtsi:58 */
			clock-frequency = < 0xd59f80 >; /* in zephyr\dts\arm\st\f0\stm32f0.dtsi:59 */
			status = "disabled";            /* in zephyr\dts\arm\st\f0\stm32f0.dtsi:60 */
		};

		/* node '/clocks/clk-lse' defined in zephyr\dts\arm\st\f0\stm32f0.dtsi:63 */
		clk_lse: clk-lse {
			#clock-cells = < 0x0 >;            /* in zephyr\dts\arm\st\f0\stm32f0.dtsi:64 */
			compatible = "st,stm32-lse-clock"; /* in zephyr\dts\arm\st\f0\stm32f0.dtsi:65 */
			clock-frequency = < 0x8000 >;      /* in zephyr\dts\arm\st\f0\stm32f0.dtsi:66 */
			driving-capability = < 0x0 >;      /* in zephyr\dts\arm\st\f0\stm32f0.dtsi:67 */
			status = "okay";                   /* in zephyr\boards\st\nucleo_f072rb\nucleo_f072rb.dts:54 */
		};

		/* node '/clocks/clk-lsi' defined in zephyr\dts\arm\st\f0\stm32f0.dtsi:71 */
		clk_lsi: clk-lsi {
			#clock-cells = < 0x0 >;       /* in zephyr\dts\arm\st\f0\stm32f0.dtsi:72 */
			compatible = "fixed-clock";   /* in zephyr\dts\arm\st\f0\stm32f0.dtsi:73 */
			clock-frequency = < 0x9c40 >; /* in zephyr\dts\arm\st\f0\stm32f0.dtsi:74 */
			status = "disabled";          /* in zephyr\dts\arm\st\f0\stm32f0.dtsi:75 */
		};

		/* node '/clocks/pll' defined in zephyr\dts\arm\st\f0\stm32f0.dtsi:78 */
		pll: pll {
			#clock-cells = < 0x0 >;              /* in zephyr\dts\arm\st\f0\stm32f0.dtsi:79 */
			compatible = "st,stm32f0-pll-clock"; /* in zephyr\dts\arm\st\f0\stm32f0.dtsi:80 */
			clocks = < &clk_hse >;               /* in zephyr\boards\st\nucleo_f072rb\nucleo_f072rb.dts:64 */
			prediv = < 0x1 >;                    /* in zephyr\boards\st\nucleo_f072rb\nucleo_f072rb.dts:65 */
			mul = < 0x6 >;                       /* in zephyr\boards\st\nucleo_f072rb\nucleo_f072rb.dts:66 */
			status = "okay";                     /* in zephyr\boards\st\nucleo_f072rb\nucleo_f072rb.dts:67 */
			phandle = < 0x3 >;                   /* in zephyr\boards\st\nucleo_f072rb\nucleo_f072rb.dts:71 */
		};

		/* node '/clocks/clk-hsi48' defined in zephyr\dts\arm\st\f0\stm32f071.dtsi:15 */
		clk_hsi48: clk-hsi48 {
			#clock-cells = < 0x0 >;          /* in zephyr\dts\arm\st\f0\stm32f071.dtsi:16 */
			compatible = "fixed-clock";      /* in zephyr\dts\arm\st\f0\stm32f071.dtsi:17 */
			clock-frequency = < 0x2dc6c00 >; /* in zephyr\dts\arm\st\f0\stm32f071.dtsi:18 */
			status = "disabled";             /* in zephyr\dts\arm\st\f0\stm32f071.dtsi:19 */
		};
	};

	/* node '/vref' defined in zephyr\dts\arm\st\f0\stm32f0.dtsi:414 */
	vref: vref {
		compatible = "st,stm32-vref";   /* in zephyr\dts\arm\st\f0\stm32f0.dtsi:415 */
		nvmem-cells = < &vrefint_otp >; /* in zephyr\dts\arm\st\f0\stm32f0.dtsi:416 */
		vrefint-cal-mv = < 0xce4 >;     /* in zephyr\dts\arm\st\f0\stm32f0.dtsi:417 */
		io-channels = < &adc1 0x11 >;   /* in zephyr\dts\arm\st\f0\stm32f0.dtsi:418 */
		status = "okay";                /* in zephyr\boards\st\nucleo_f072rb\nucleo_f072rb.dts:141 */
	};

	/* node '/smbus1' defined in zephyr\dts\arm\st\f0\stm32f0.dtsi:422 */
	smbus1: smbus1 {
		compatible = "st,stm32-smbus"; /* in zephyr\dts\arm\st\f0\stm32f0.dtsi:423 */
		#address-cells = < 0x1 >;      /* in zephyr\dts\arm\st\f0\stm32f0.dtsi:424 */
		#size-cells = < 0x0 >;         /* in zephyr\dts\arm\st\f0\stm32f0.dtsi:425 */
		i2c = < &i2c1 >;               /* in zephyr\dts\arm\st\f0\stm32f0.dtsi:426 */
		status = "disabled";           /* in zephyr\dts\arm\st\f0\stm32f0.dtsi:427 */
	};

	/* node '/dietemp' defined in zephyr\dts\arm\st\f0\stm32f031.dtsi:57 */
	die_temp: dietemp {
		compatible = "st,stm32-temp-cal"; /* in zephyr\dts\arm\st\f0\stm32f031.dtsi:58 */
		nvmem-cells = < &ts_cal1_otp >,
		              < &ts_cal2_otp >;   /* in zephyr\dts\arm\st\f0\stm32f031.dtsi:59 */
		nvmem-cell-names = "TS_CAL1",
		                   "TS_CAL2";     /* in zephyr\dts\arm\st\f0\stm32f031.dtsi:60 */
		ts-cal1-temp = < 0x1e >;          /* in zephyr\dts\arm\st\f0\stm32f031.dtsi:61 */
		ts-cal2-temp = < 0x6e >;          /* in zephyr\dts\arm\st\f0\stm32f031.dtsi:62 */
		ts-cal-vrefanalog = < 0xce4 >;    /* in zephyr\dts\arm\st\f0\stm32f031.dtsi:63 */
		io-channels = < &adc1 0x10 >;     /* in zephyr\dts\arm\st\f0\stm32f031.dtsi:64 */
		status = "okay";                  /* in zephyr\boards\st\nucleo_f072rb\nucleo_f072rb.dts:137 */
	};

	/* node '/vbat' defined in zephyr\dts\arm\st\f0\stm32f031.dtsi:69 */
	vbat: vbat {
		compatible = "st,stm32-vbat"; /* in zephyr\dts\arm\st\f0\stm32f031.dtsi:70 */
		ratio = < 0x2 >;              /* in zephyr\dts\arm\st\f0\stm32f031.dtsi:71 */
		io-channels = < &adc1 0x12 >; /* in zephyr\dts\arm\st\f0\stm32f031.dtsi:72 */
		status = "disabled";          /* in zephyr\dts\arm\st\f0\stm32f031.dtsi:73 */
	};

	/* node '/smbus2' defined in zephyr\dts\arm\st\f0\stm32f051.dtsi:94 */
	smbus2: smbus2 {
		compatible = "st,stm32-smbus"; /* in zephyr\dts\arm\st\f0\stm32f051.dtsi:95 */
		#address-cells = < 0x1 >;      /* in zephyr\dts\arm\st\f0\stm32f051.dtsi:96 */
		#size-cells = < 0x0 >;         /* in zephyr\dts\arm\st\f0\stm32f051.dtsi:97 */
		i2c = < &i2c2 >;               /* in zephyr\dts\arm\st\f0\stm32f051.dtsi:98 */
		status = "disabled";           /* in zephyr\dts\arm\st\f0\stm32f051.dtsi:99 */
	};

	/* node '/usbphy' defined in zephyr\dts\arm\st\f0\stm32f072.dtsi:36 */
	usb_fs_phy: usbphy {
		compatible = "usb-nop-xceiv"; /* in zephyr\dts\arm\st\f0\stm32f072.dtsi:37 */
		#phy-cells = < 0x0 >;         /* in zephyr\dts\arm\st\f0\stm32f072.dtsi:38 */
		phandle = < 0x1a >;           /* in zephyr\dts\arm\st\f0\stm32f072.dtsi:29 */
	};

	/* node '/connector' defined in zephyr\boards\st\nucleo_f072rb\arduino_r3_connector.dtsi:10 */
	arduino_header: connector {
		compatible = "arduino-header-r3";          /* in zephyr\boards\st\nucleo_f072rb\arduino_r3_connector.dtsi:11 */
		#gpio-cells = < 0x2 >;                     /* in zephyr\boards\st\nucleo_f072rb\arduino_r3_connector.dtsi:12 */
		gpio-map-mask = < 0xffffffff 0xffffffc0 >; /* in zephyr\boards\st\nucleo_f072rb\arduino_r3_connector.dtsi:13 */
		gpio-map-pass-thru = < 0x0 0x3f >;         /* in zephyr\boards\st\nucleo_f072rb\arduino_r3_connector.dtsi:14 */
		gpio-map = < 0x0 0x0 &gpioa 0x0 0x0 >,
		           < 0x1 0x0 &gpioa 0x1 0x0 >,
		           < 0x2 0x0 &gpioa 0x4 0x0 >,
		           < 0x3 0x0 &gpiob 0x0 0x0 >,
		           < 0x4 0x0 &gpioc 0x1 0x0 >,
		           < 0x5 0x0 &gpioc 0x0 0x0 >,
		           < 0x6 0x0 &gpioa 0x3 0x0 >,
		           < 0x7 0x0 &gpioa 0x2 0x0 >,
		           < 0x8 0x0 &gpioa 0xa 0x0 >,
		           < 0x9 0x0 &gpiob 0x3 0x0 >,
		           < 0xa 0x0 &gpiob 0x5 0x0 >,
		           < 0xb 0x0 &gpiob 0x4 0x0 >,
		           < 0xc 0x0 &gpiob 0xa 0x0 >,
		           < 0xd 0x0 &gpioa 0x8 0x0 >,
		           < 0xe 0x0 &gpioa 0x9 0x0 >,
		           < 0xf 0x0 &gpioc 0x7 0x0 >,
		           < 0x10 0x0 &gpiob 0x6 0x0 >,
		           < 0x11 0x0 &gpioa 0x7 0x0 >,
		           < 0x12 0x0 &gpioa 0x6 0x0 >,
		           < 0x13 0x0 &gpioa 0x5 0x0 >,
		           < 0x14 0x0 &gpiob 0x9 0x0 >,
		           < 0x15 0x0 &gpiob 0x8 0x0 >;    /* in zephyr\boards\st\nucleo_f072rb\arduino_r3_connector.dtsi:15 */
	};

	/* node '/st-morpho-header' defined in zephyr\boards\st\nucleo_f072rb\st_morpho_connector.dtsi:10 */
	st_morpho_header: st-morpho-header {
		compatible = "st-morpho-header";        /* in zephyr\boards\st\nucleo_f072rb\st_morpho_connector.dtsi:11 */
		#gpio-cells = < 0x2 >;                  /* in zephyr\boards\st\nucleo_f072rb\st_morpho_connector.dtsi:12 */
		gpio-map-mask = < 0xff 0x0 >;           /* in zephyr\boards\st\nucleo_f072rb\st_morpho_connector.dtsi:13 */
		gpio-map-pass-thru = < 0x0 0x7f >;      /* in zephyr\boards\st\nucleo_f072rb\st_morpho_connector.dtsi:14 */
		gpio-map = < 0x0 0x0 &gpioc 0xa 0x0 >,
		           < 0x1 0x0 &gpioc 0xb 0x0 >,
		           < 0x2 0x0 &gpioc 0xc 0x0 >,
		           < 0x3 0x0 &gpiod 0x2 0x0 >,
		           < 0x8 0x0 &gpiof 0x6 0x0 >,
		           < 0xa 0x0 &gpiof 0x7 0x0 >,
		           < 0xc 0x0 &gpioa 0xd 0x0 >,
		           < 0xe 0x0 &gpioa 0xe 0x0 >,
		           < 0x10 0x0 &gpioa 0xf 0x0 >,
		           < 0x14 0x0 &gpiob 0x7 0x0 >,
		           < 0x16 0x0 &gpioc 0xd 0x0 >,
		           < 0x18 0x0 &gpioc 0xe 0x0 >,
		           < 0x1a 0x0 &gpioc 0xf 0x0 >,
		           < 0x1b 0x0 &gpioa 0x0 0x0 >,
		           < 0x1c 0x0 &gpiof 0x0 0x0 >,
		           < 0x1d 0x0 &gpioa 0x1 0x0 >,
		           < 0x1e 0x0 &gpiof 0x1 0x0 >,
		           < 0x1f 0x0 &gpioa 0x4 0x0 >,
		           < 0x21 0x0 &gpiob 0x0 0x0 >,
		           < 0x22 0x0 &gpioc 0x2 0x0 >,
		           < 0x23 0x0 &gpioc 0x1 0x0 >,
		           < 0x24 0x0 &gpioc 0x3 0x0 >,
		           < 0x25 0x0 &gpioc 0x0 0x0 >,
		           < 0x48 0x0 &gpioc 0x9 0x0 >,
		           < 0x49 0x0 &gpioc 0x8 0x0 >,
		           < 0x4a 0x0 &gpiob 0x8 0x0 >,
		           < 0x4b 0x0 &gpioc 0x6 0x0 >,
		           < 0x4c 0x0 &gpiob 0x9 0x0 >,
		           < 0x4d 0x0 &gpioc 0x5 0x0 >,
		           < 0x51 0x0 &gpiod 0x8 0x0 >,
		           < 0x52 0x0 &gpioa 0x5 0x0 >,
		           < 0x53 0x0 &gpioa 0xc 0x0 >,
		           < 0x54 0x0 &gpioa 0x6 0x0 >,
		           < 0x55 0x0 &gpioa 0xb 0x0 >,
		           < 0x56 0x0 &gpioa 0x7 0x0 >,
		           < 0x57 0x0 &gpiob 0xc 0x0 >,
		           < 0x58 0x0 &gpiob 0x6 0x0 >,
		           < 0x59 0x0 &gpiob 0xb 0x0 >,
		           < 0x5a 0x0 &gpioc 0x7 0x0 >,
		           < 0x5c 0x0 &gpioa 0x9 0x0 >,
		           < 0x5d 0x0 &gpiob 0x2 0x0 >,
		           < 0x5e 0x0 &gpioa 0x8 0x0 >,
		           < 0x5f 0x0 &gpiob 0x1 0x0 >,
		           < 0x60 0x0 &gpiob 0xa 0x0 >,
		           < 0x61 0x0 &gpiob 0xf 0x0 >,
		           < 0x62 0x0 &gpiob 0x4 0x0 >,
		           < 0x63 0x0 &gpiob 0xe 0x0 >,
		           < 0x64 0x0 &gpiob 0x5 0x0 >,
		           < 0x65 0x0 &gpiob 0xd 0x0 >,
		           < 0x66 0x0 &gpiob 0x3 0x0 >,
		           < 0x68 0x0 &gpioa 0xa 0x0 >,
		           < 0x69 0x0 &gpioc 0x4 0x0 >,
		           < 0x6a 0x0 &gpioa 0x2 0x0 >,
		           < 0x6b 0x0 &gpiof 0x5 0x0 >,
		           < 0x6c 0x0 &gpioa 0x3 0x0 >,
		           < 0x6d 0x0 &gpiof 0x4 0x0 >; /* in zephyr\boards\st\nucleo_f072rb\st_morpho_connector.dtsi:15 */
	};

	/* node '/leds' defined in zephyr\boards\st\nucleo_f072rb\nucleo_f072rb.dts:25 */
	leds: leds {
		compatible = "gpio-leds"; /* in zephyr\boards\st\nucleo_f072rb\nucleo_f072rb.dts:26 */

		/* node '/leds/led_2' defined in zephyr\boards\st\nucleo_f072rb\nucleo_f072rb.dts:28 */
		green_led_2: led_2 {
			gpios = < &gpioa 0x5 0x0 >; /* in zephyr\boards\st\nucleo_f072rb\nucleo_f072rb.dts:29 */
			label = "User LD2";         /* in zephyr\boards\st\nucleo_f072rb\nucleo_f072rb.dts:30 */
		};
	};

	/* node '/gpio_keys' defined in zephyr\boards\st\nucleo_f072rb\nucleo_f072rb.dts:34 */
	gpio_keys {
		compatible = "gpio-keys"; /* in zephyr\boards\st\nucleo_f072rb\nucleo_f072rb.dts:35 */

		/* node '/gpio_keys/button' defined in zephyr\boards\st\nucleo_f072rb\nucleo_f072rb.dts:37 */
		user_button: button {
			label = "User";             /* in zephyr\boards\st\nucleo_f072rb\nucleo_f072rb.dts:38 */
			gpios = < &gpioc 0xd 0x1 >; /* in zephyr\boards\st\nucleo_f072rb\nucleo_f072rb.dts:39 */
			zephyr,code = < 0xb >;      /* in zephyr\boards\st\nucleo_f072rb\nucleo_f072rb.dts:40 */
		};
	};

	/* node '/motors' defined in ..\Documents\capstone\zephyr\nucleo_f072rb.overlay:66 */
	motors: motors {
		compatible = "capstone,mecanum-motors"; /* in ..\Documents\capstone\zephyr\nucleo_f072rb.overlay:67 */
		pwms = < &pwm2 0x1 0xc350 0x0 >,
		       < &pwm2 0x2 0xc350 0x0 >,
		       < &pwm3 0x3 0xc350 0x0 >,
		       < &pwm3 0x4 0xc350 0x0 >;        /* in ..\Documents\capstone\zephyr\nucleo_f072rb.overlay:69 */
		dir-gpios = < &gpioc 0x0 0x0 >,
		            < &gpioc 0x1 0x0 >,
		            < &gpioc 0x2 0x0 >,
		            < &gpioc 0x3 0x0 >;         /* in ..\Documents\capstone\zephyr\nucleo_f072rb.overlay:74 */
	};

	/* node '/gripper' defined in ..\Documents\capstone\zephyr\nucleo_f072rb.overlay:80 */
	gripper: gripper {
		compatible = "capstone,gripper";    /* in ..\Documents\capstone\zephyr\nucleo_f072rb.overlay:81 */
		pwms = < &pwm1 0x1 0x1312d00 0x0 >; /* in ..\Documents\capstone\zephyr\nucleo_f072rb.overlay:83 */
	};

	/* node '/hopper' defined in ..\Documents\capstone\zephyr\nucleo_f072rb.overlay:86 */
	hopper: hopper {
		compatible = "capstone,hopper";  /* in ..\Documents\capstone\zephyr\nucleo_f072rb.overlay:87 */
		ain1-gpios = < &gpiob 0x8 0x0 >; /* in ..\Documents\capstone\zephyr\nucleo_f072rb.overlay:89 */
		ain2-gpios = < &gpiob 0x9 0x0 >; /* in ..\Documents\capstone\zephyr\nucleo_f072rb.overlay:90 */
	};
};
